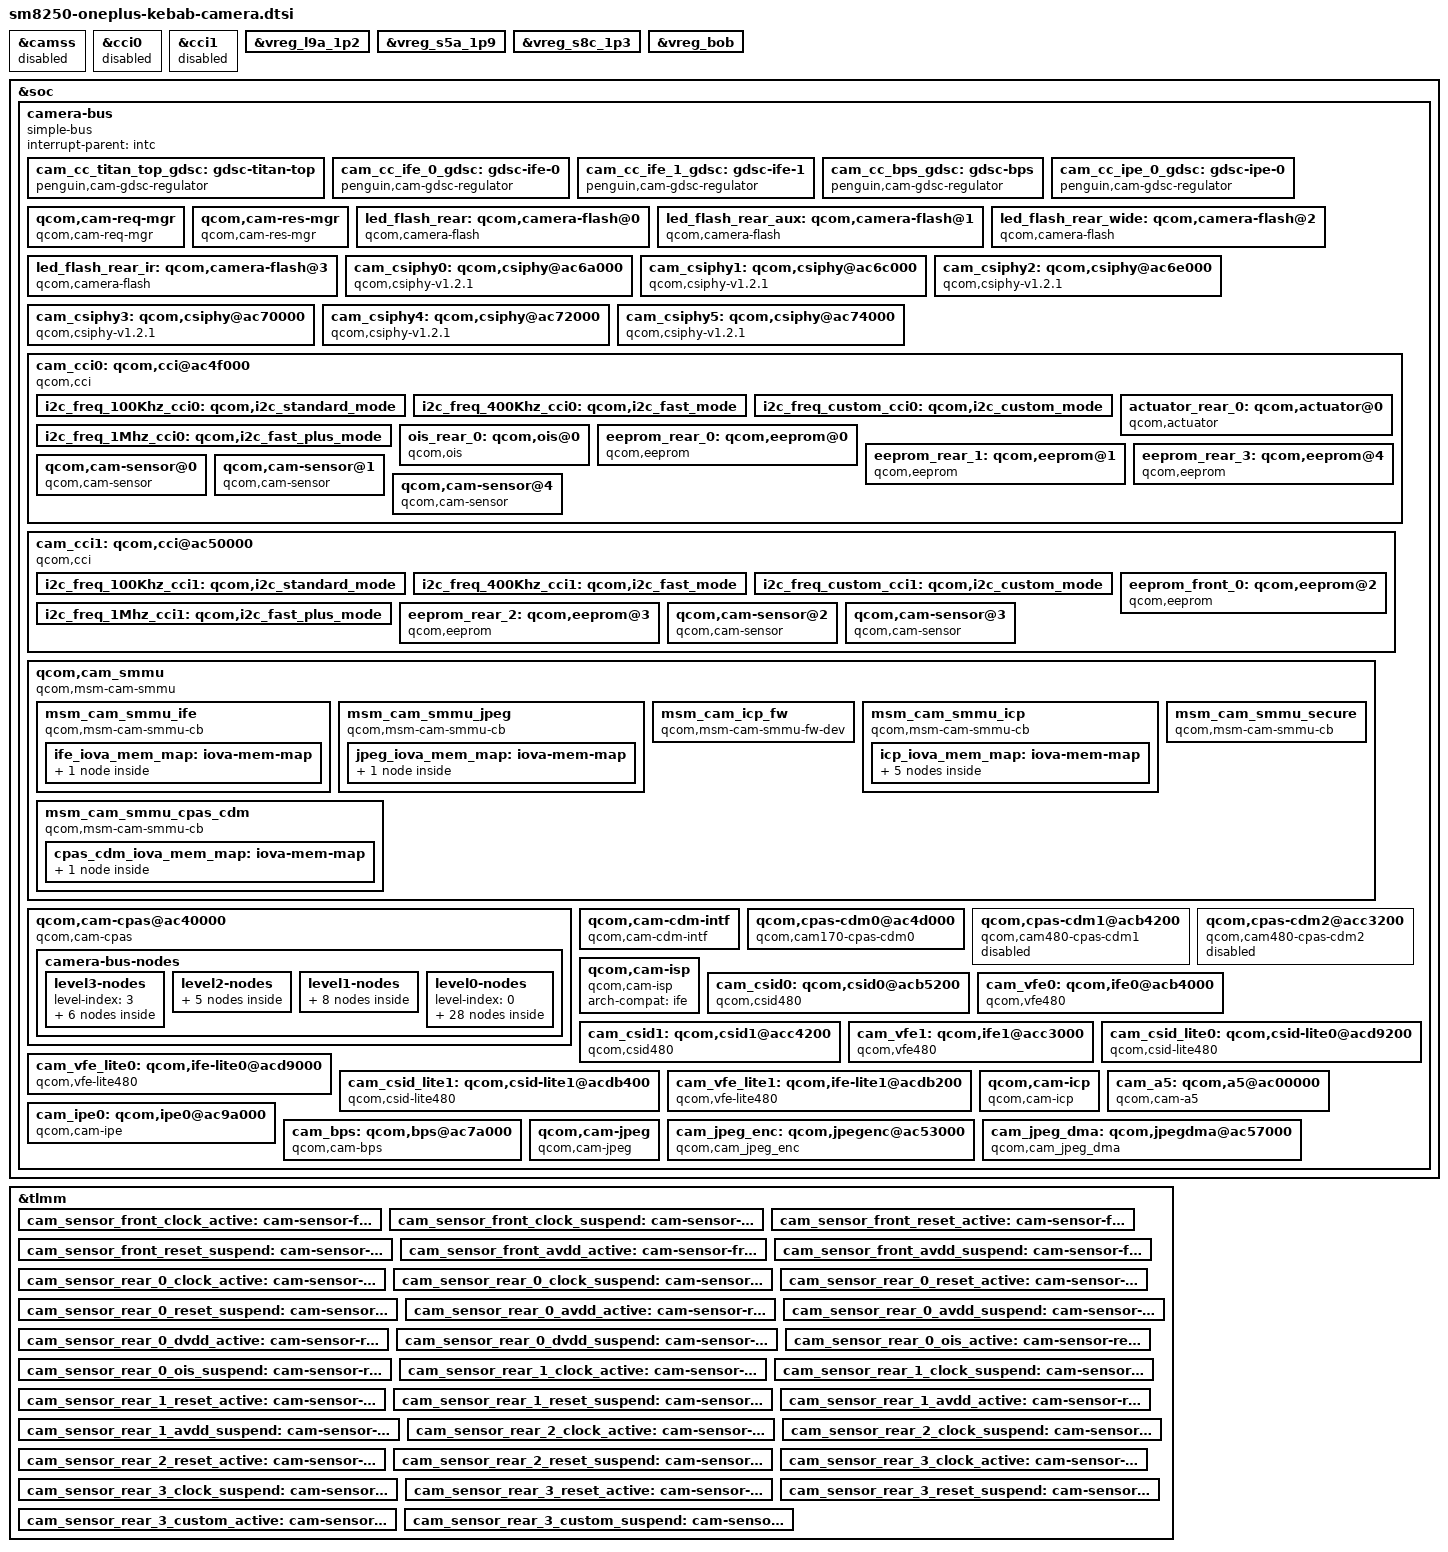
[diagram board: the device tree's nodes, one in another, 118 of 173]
// SPDX-License-Identifier: BSD-3-Clause
/*
 * Qualcomm Titan 480 camera subsystem and OnePlus 8T (kebab) sensor topology
 * for out-of-tree kona-camera-kernel on mainline Linux 6.18.
 */

#include <dt-bindings/clock/qcom,camcc-sm8250.h>
#include <dt-bindings/clock/qcom,gcc-sm8250.h>
#include <dt-bindings/interconnect/qcom,icc.h>
#include <dt-bindings/interconnect/qcom,sm8250.h>
#include <dt-bindings/msm-camera.h>
#include <dt-bindings/power/qcom,rpmhpd.h>
#include <dt-bindings/regulator/qcom,rpmh-regulator.h>

/* Keep mainline CAMSS and CCI disabled so kona-camera-kernel owns Titan 480. */
&camss {
	status = "disabled";
};

&cci0 {
	status = "disabled";
};

&cci1 {
	status = "disabled";
};

/* Allow camera drivers to vote regulator loads on shared RPMh rails. */
&vreg_l9a_1p2 {
	regulator-allow-set-load;
	regulator-allowed-modes = <RPMH_REGULATOR_MODE_HPM>;
};

&vreg_s5a_1p9 {
	regulator-allow-set-load;
	regulator-allowed-modes = <RPMH_REGULATOR_MODE_HPM>;
};

&vreg_s8c_1p3 {
	regulator-allow-set-load;
	regulator-allowed-modes = <RPMH_REGULATOR_MODE_HPM>;
};

&vreg_bob {
	regulator-allow-set-load;
	regulator-allowed-modes = <RPMH_REGULATOR_MODE_AUTO RPMH_REGULATOR_MODE_HPM>;
};

&soc {
	camera-bus {
		compatible = "simple-bus";
		#address-cells = <1>;
		#size-cells = <1>;
		ranges = <0x0 0x0 0x0 0xffffffff>;
		interrupt-parent = <&intc>;

		/* Mainline genpd -> regulator bridges for kona-camera-kernel */
		cam_cc_titan_top_gdsc: gdsc-titan-top {
			compatible = "penguin,cam-gdsc-regulator";
			regulator-name = "titan_top_gdsc";
			power-domains = <&camcc TITAN_TOP_GDSC>;
		};

		cam_cc_ife_0_gdsc: gdsc-ife-0 {
			compatible = "penguin,cam-gdsc-regulator";
			regulator-name = "ife_0_gdsc";
			power-domains = <&camcc IFE_0_GDSC>;
		};

		cam_cc_ife_1_gdsc: gdsc-ife-1 {
			compatible = "penguin,cam-gdsc-regulator";
			regulator-name = "ife_1_gdsc";
			power-domains = <&camcc IFE_1_GDSC>;
		};

		cam_cc_bps_gdsc: gdsc-bps {
			compatible = "penguin,cam-gdsc-regulator";
			regulator-name = "bps_gdsc";
			power-domains = <&camcc BPS_GDSC>;
		};

		cam_cc_ipe_0_gdsc: gdsc-ipe-0 {
			compatible = "penguin,cam-gdsc-regulator";
			regulator-name = "ipe_0_gdsc";
			power-domains = <&camcc IPE_0_GDSC>;
		};

		qcom,cam-req-mgr {
			compatible = "qcom,cam-req-mgr";
			status = "okay";
		};

		qcom,cam-res-mgr {
			compatible = "qcom,cam-res-mgr";
			status = "okay";
		};

		led_flash_rear: qcom,camera-flash@0 {
			cell-index = <0>;
			compatible = "qcom,camera-flash";
			flash-type = <CAM_FLASH_TYPE_PMIC>;
			leds = <&pm8150l_flash_led0>;
			status = "okay";
		};

		led_flash_rear_aux: qcom,camera-flash@1 {
			cell-index = <1>;
			compatible = "qcom,camera-flash";
			flash-type = <CAM_FLASH_TYPE_PMIC>;
			leds = <&pm8150l_flash_led0>;
			status = "okay";
		};

		led_flash_rear_wide: qcom,camera-flash@2 {
			cell-index = <2>;
			compatible = "qcom,camera-flash";
			flash-type = <CAM_FLASH_TYPE_PMIC>;
			leds = <&pm8150l_flash_led0>;
			status = "okay";
		};

		led_flash_rear_ir: qcom,camera-flash@3 {
			cell-index = <3>;
			compatible = "qcom,camera-flash";
			flash-type = <CAM_FLASH_TYPE_PMIC>;
			leds = <&pm8150l_flash_led0>;
			status = "okay";
		};

		cam_csiphy0: qcom,csiphy@ac6a000 {
			cell-index = <0>;
			compatible = "qcom,csiphy-v1.2.1", "qcom,csiphy";
			reg = <0x0ac6a000 0x2000>;
			reg-names = "csiphy";
			reg-cam-base = <0x6a000>;
			interrupts = <GIC_SPI 477 IRQ_TYPE_EDGE_RISING>;
			interrupt-names = "csiphy";
			gdscr-supply = <&cam_cc_titan_top_gdsc>;
			refgen-supply = <&refgen>;
			regulator-names = "gdscr", "refgen";
			csi-vdd-voltage = <1200000>;
			mipi-csi-vdd-supply = <&vreg_l9a_1p2>;
			clocks = <&camcc CAM_CC_CPHY_RX_CLK_SRC>,
				 <&camcc CAM_CC_CSIPHY0_CLK>,
				 <&camcc CAM_CC_CSI0PHYTIMER_CLK_SRC>,
				 <&camcc CAM_CC_CSI0PHYTIMER_CLK>;
			clock-names = "cphy_rx_clk_src",
				      "csiphy0_clk",
				      "csi0phytimer_clk_src",
				      "csi0phytimer_clk";
			src-clock-name = "csi0phytimer_clk_src";
			clock-cntl-level = "turbo";
			clock-rates = <400000000 0 300000000 0>;
			status = "okay";
		};

		cam_csiphy1: qcom,csiphy@ac6c000 {
			cell-index = <1>;
			compatible = "qcom,csiphy-v1.2.1", "qcom,csiphy";
			reg = <0x0ac6c000 0x2000>;
			reg-names = "csiphy";
			reg-cam-base = <0x6c000>;
			interrupts = <GIC_SPI 478 IRQ_TYPE_EDGE_RISING>;
			interrupt-names = "csiphy";
			gdscr-supply = <&cam_cc_titan_top_gdsc>;
			refgen-supply = <&refgen>;
			regulator-names = "gdscr", "refgen";
			csi-vdd-voltage = <1200000>;
			mipi-csi-vdd-supply = <&vreg_l9a_1p2>;
			clocks = <&camcc CAM_CC_CPHY_RX_CLK_SRC>,
				 <&camcc CAM_CC_CSIPHY1_CLK>,
				 <&camcc CAM_CC_CSI1PHYTIMER_CLK_SRC>,
				 <&camcc CAM_CC_CSI1PHYTIMER_CLK>;
			clock-names = "cphy_rx_clk_src",
				      "csiphy1_clk",
				      "csi1phytimer_clk_src",
				      "csi1phytimer_clk";
			src-clock-name = "csi1phytimer_clk_src";
			clock-cntl-level = "turbo";
			clock-rates = <400000000 0 300000000 0>;
			status = "okay";
		};

		cam_csiphy2: qcom,csiphy@ac6e000 {
			cell-index = <2>;
			compatible = "qcom,csiphy-v1.2.1", "qcom,csiphy";
			reg = <0x0ac6e000 0x2000>;
			reg-names = "csiphy";
			reg-cam-base = <0x6e000>;
			interrupts = <GIC_SPI 479 IRQ_TYPE_EDGE_RISING>;
			interrupt-names = "csiphy";
			gdscr-supply = <&cam_cc_titan_top_gdsc>;
			refgen-supply = <&refgen>;
			regulator-names = "gdscr", "refgen";
			csi-vdd-voltage = <1200000>;
			mipi-csi-vdd-supply = <&vreg_l9a_1p2>;
			clocks = <&camcc CAM_CC_CPHY_RX_CLK_SRC>,
				 <&camcc CAM_CC_CSIPHY2_CLK>,
				 <&camcc CAM_CC_CSI2PHYTIMER_CLK_SRC>,
				 <&camcc CAM_CC_CSI2PHYTIMER_CLK>;
			clock-names = "cphy_rx_clk_src",
				      "csiphy2_clk",
				      "csi2phytimer_clk_src",
				      "csi2phytimer_clk";
			src-clock-name = "csi2phytimer_clk_src";
			clock-cntl-level = "turbo";
			clock-rates = <400000000 0 300000000 0>;
			status = "okay";
		};

		cam_csiphy3: qcom,csiphy@ac70000 {
			cell-index = <3>;
			compatible = "qcom,csiphy-v1.2.1", "qcom,csiphy";
			reg = <0x0ac70000 0x2000>;
			reg-names = "csiphy";
			reg-cam-base = <0x70000>;
			interrupts = <GIC_SPI 448 IRQ_TYPE_EDGE_RISING>;
			interrupt-names = "csiphy";
			gdscr-supply = <&cam_cc_titan_top_gdsc>;
			refgen-supply = <&refgen>;
			regulator-names = "gdscr", "refgen";
			csi-vdd-voltage = <1200000>;
			mipi-csi-vdd-supply = <&vreg_l9a_1p2>;
			clocks = <&camcc CAM_CC_CPHY_RX_CLK_SRC>,
				 <&camcc CAM_CC_CSIPHY3_CLK>,
				 <&camcc CAM_CC_CSI3PHYTIMER_CLK_SRC>,
				 <&camcc CAM_CC_CSI3PHYTIMER_CLK>;
			clock-names = "cphy_rx_clk_src",
				      "csiphy3_clk",
				      "csi3phytimer_clk_src",
				      "csi3phytimer_clk";
			src-clock-name = "csi3phytimer_clk_src";
			clock-cntl-level = "turbo";
			clock-rates = <400000000 0 300000000 0>;
			status = "okay";
		};

		cam_csiphy4: qcom,csiphy@ac72000 {
			cell-index = <4>;
			compatible = "qcom,csiphy-v1.2.1", "qcom,csiphy";
			reg = <0x0ac72000 0x2000>;
			reg-names = "csiphy";
			reg-cam-base = <0x72000>;
			interrupts = <GIC_SPI 86 IRQ_TYPE_EDGE_RISING>;
			interrupt-names = "csiphy";
			gdscr-supply = <&cam_cc_titan_top_gdsc>;
			refgen-supply = <&refgen>;
			regulator-names = "gdscr", "refgen";
			csi-vdd-voltage = <1200000>;
			mipi-csi-vdd-supply = <&vreg_l9a_1p2>;
			clocks = <&camcc CAM_CC_CPHY_RX_CLK_SRC>,
				 <&camcc CAM_CC_CSIPHY4_CLK>,
				 <&camcc CAM_CC_CSI4PHYTIMER_CLK_SRC>,
				 <&camcc CAM_CC_CSI4PHYTIMER_CLK>;
			clock-names = "cphy_rx_clk_src",
				      "csiphy4_clk",
				      "csi4phytimer_clk_src",
				      "csi4phytimer_clk";
			src-clock-name = "csi4phytimer_clk_src";
			clock-cntl-level = "turbo";
			clock-rates = <400000000 0 300000000 0>;
			status = "okay";
		};

		cam_csiphy5: qcom,csiphy@ac74000 {
			cell-index = <5>;
			compatible = "qcom,csiphy-v1.2.1", "qcom,csiphy";
			reg = <0x0ac74000 0x2000>;
			reg-names = "csiphy";
			reg-cam-base = <0x74000>;
			interrupts = <GIC_SPI 89 IRQ_TYPE_EDGE_RISING>;
			interrupt-names = "csiphy";
			gdscr-supply = <&cam_cc_titan_top_gdsc>;
			refgen-supply = <&refgen>;
			regulator-names = "gdscr", "refgen";
			csi-vdd-voltage = <1200000>;
			mipi-csi-vdd-supply = <&vreg_l9a_1p2>;
			clocks = <&camcc CAM_CC_CPHY_RX_CLK_SRC>,
				 <&camcc CAM_CC_CSIPHY5_CLK>,
				 <&camcc CAM_CC_CSI5PHYTIMER_CLK_SRC>,
				 <&camcc CAM_CC_CSI5PHYTIMER_CLK>;
			clock-names = "cphy_rx_clk_src",
				      "csiphy5_clk",
				      "csi5phytimer_clk_src",
				      "csi5phytimer_clk";
			src-clock-name = "csi5phytimer_clk_src";
			clock-cntl-level = "turbo";
			clock-rates = <400000000 0 300000000 0>;
			status = "okay";
		};

		cam_cci0: qcom,cci@ac4f000 {
			cell-index = <0>;
			compatible = "qcom,cci";
			#address-cells = <1>;
			#size-cells = <0>;
			reg = <0x0ac4f000 0x1000>;
			reg-names = "cci";
			reg-cam-base = <0x4f000>;
			interrupt-names = "cci";
			interrupts = <GIC_SPI 460 IRQ_TYPE_EDGE_RISING>;
			status = "okay";
			gdscr-supply = <&cam_cc_titan_top_gdsc>;
			regulator-names = "gdscr";
			clocks = <&camcc CAM_CC_CCI_0_CLK_SRC>,
				 <&camcc CAM_CC_CCI_0_CLK>;
			clock-names = "cci_0_clk_src",
				      "cci_0_clk";
			src-clock-name = "cci_0_clk_src";
			clock-cntl-level = "lowsvs";
			clock-rates = <37500000 0>;
			pinctrl-names = "cam_default", "cam_suspend";
			pinctrl-0 = <&cci0_default>;
			pinctrl-1 = <&cci0_sleep>;
			qcom,cam-gpio-list = <&tlmm 101 0>,
					     <&tlmm 102 0>,
					     <&tlmm 103 0>,
					     <&tlmm 104 0>;
			gpio-req-tbl-num = <0 1 2 3>;
			gpio-req-tbl-flags = <1 1 1 1>;
			gpio-req-tbl-label = "CCI_I2C_DATA0",
					     "CCI_I2C_CLK0",
					     "CCI_I2C_DATA1",
					     "CCI_I2C_CLK1";

			i2c_freq_100Khz_cci0: qcom,i2c_standard_mode {
				hw-thigh = <201>;
				hw-tlow = <174>;
				hw-tsu-sto = <204>;
				hw-tsu-sta = <231>;
				hw-thd-dat = <22>;
				hw-thd-sta = <162>;
				hw-tbuf = <227>;
				hw-scl-stretch-en = <0>;
				hw-trdhld = <6>;
				hw-tsp = <3>;
				cci-clk-src = <37500000>;
				status = "okay";
			};

			i2c_freq_400Khz_cci0: qcom,i2c_fast_mode {
				hw-thigh = <38>;
				hw-tlow = <56>;
				hw-tsu-sto = <40>;
				hw-tsu-sta = <40>;
				hw-thd-dat = <22>;
				hw-thd-sta = <35>;
				hw-tbuf = <62>;
				hw-scl-stretch-en = <0>;
				hw-trdhld = <6>;
				hw-tsp = <3>;
				cci-clk-src = <37500000>;
				status = "okay";
			};

			i2c_freq_custom_cci0: qcom,i2c_custom_mode {
				hw-thigh = <38>;
				hw-tlow = <56>;
				hw-tsu-sto = <40>;
				hw-tsu-sta = <40>;
				hw-thd-dat = <22>;
				hw-thd-sta = <35>;
				hw-tbuf = <62>;
				hw-scl-stretch-en = <1>;
				hw-trdhld = <6>;
				hw-tsp = <3>;
				cci-clk-src = <37500000>;
				status = "okay";
			};

			i2c_freq_1Mhz_cci0: qcom,i2c_fast_plus_mode {
				hw-thigh = <16>;
				hw-tlow = <22>;
				hw-tsu-sto = <17>;
				hw-tsu-sta = <18>;
				hw-thd-dat = <16>;
				hw-thd-sta = <15>;
				hw-tbuf = <24>;
				hw-scl-stretch-en = <0>;
				hw-trdhld = <3>;
				hw-tsp = <3>;
				cci-clk-src = <37500000>;
				status = "okay";
			};

			actuator_rear_0: qcom,actuator@0 {
				cell-index = <0>;
				reg = <0x0>;
				compatible = "qcom,actuator";
				cci-master = <0>;
				cam_vaf-supply = <&pm8008_l3>;
				regulator-names = "cam_vaf";
				rgltr-cntrl-support;
				rgltr-min-voltage = <2800000>;
				rgltr-max-voltage = <2800000>;
				rgltr-load-current = <600000>;
			};

			ois_rear_0: qcom,ois@0 {
				cell-index = <0>;
				reg = <0x0>;
				compatible = "qcom,ois";
				cam_vio-supply = <&pm8008_l4>;
				cam_vdig-supply = <&vreg_s8c_1p3>;
				cam_vaf-supply = <&vreg_bob>;
				regulator-names = "cam_vio", "cam_vdig", "cam_vaf";
				rgltr-cntrl-support;
				rgltr-min-voltage = <0 1352000 3008000>;
				rgltr-max-voltage = <0 1352000 3800000>;
				rgltr-load-current = <1000000 1000000 1000000>;
				gpio-no-mux = <0>;
				pinctrl-names = "cam_default", "cam_suspend";
				pinctrl-0 = <&cam_sensor_rear_0_ois_active>;
				pinctrl-1 = <&cam_sensor_rear_0_ois_suspend>;
				qcom,cam-gpio-list = <&tlmm 140 0>;
				gpio-vaf = <0>;
				gpio-req-tbl-num = <0>;
				gpio-req-tbl-flags = <0>;
				gpio-req-tbl-label = "CAMIF_vaf";
				cci-master = <0>;
				status = "okay";
				ois_gyro,position = <3>;
				ois,type = <0>;
				ois_gyro,type = <3>;
				ois,name = "LC898124";
				ois_module,vendor = <0>;
				ois_actuator,vednor = <0>;
				ois,fw = <1>;
				download,fw = <1>;
			};

			/* EEPROM wide camera: IMX586 */
			eeprom_rear_0: qcom,eeprom@0 {
				cell-index = <0>;
				compatible = "qcom,eeprom";
				reg = <0x0>;
				cam_vio-supply = <&pm8008_l4>;
				cam_vdig-supply = <&vreg_s8c_1p3>;
				cam_vana-supply = <&pm8008_l7>;
				cam_v_custom1-supply = <&vreg_s5a_1p9>;
				cam_clk-supply = <&cam_cc_titan_top_gdsc>;
				regulator-names = "cam_vio", "cam_vdig", "cam_vana",
						  "cam_v_custom1", "cam_clk";
				rgltr-cntrl-support;
				rgltr-min-voltage = <0 1352000 2896000 2000000 0>;
				rgltr-max-voltage = <0 1352000 2904000 2000000 0>;
				rgltr-load-current = <1000000 1000000 300000 300000 0>;
				gpio-no-mux = <0>;
				pinctrl-names = "cam_default", "cam_suspend";
				pinctrl-0 = <&cam_sensor_rear_0_clock_active
					     &cam_sensor_rear_0_reset_active
					     &cam_sensor_rear_0_avdd_active
					     &cam_sensor_rear_0_dvdd_active>;
				pinctrl-1 = <&cam_sensor_rear_0_clock_suspend
					     &cam_sensor_rear_0_reset_suspend
					     &cam_sensor_rear_0_avdd_suspend
					     &cam_sensor_rear_0_dvdd_suspend>;
				qcom,cam-gpio-list = <&tlmm 94 0>,
						     <&tlmm 78 0>,
						     <&tlmm 139 0>,
						     <&tlmm 117 0>;
				use-shared-clk;
				gpio-reset = <1>;
				gpio-custom1 = <2>;
				gpio-vdig = <3>;
				gpio-req-tbl-num = <0 1 2 3>;
				gpio-req-tbl-flags = <1 0 0 0>;
				gpio-req-tbl-label = "CAM_MCLK0",
						     "CAM_RESET0",
						     "CAM_CUSTOM1",
						     "CAM_VDIG";
				sensor-mode = <0>;
				cci-master = <0>;
				status = "okay";
				clocks = <&camcc CAM_CC_MCLK0_CLK>;
				clock-names = "cam_clk";
				clock-cntl-level = "turbo";
				clock-rates = <19200000>;
			};

			/* EEPROM ultrawide camera: IMX481 */
			eeprom_rear_1: qcom,eeprom@1 {
				cell-index = <1>;
				compatible = "qcom,eeprom";
				reg = <0x1>;
				cam_vio-supply = <&pm8008_l4>;
				cam_vana-supply = <&vreg_bob>;
				cam_vdig-supply = <&pm8008_l1>;
				cam_clk-supply = <&cam_cc_titan_top_gdsc>;
				regulator-names = "cam_vio", "cam_vdig", "cam_vana", "cam_clk";
				rgltr-cntrl-support;
				rgltr-min-voltage = <0 1096000 3008000 0>;
				rgltr-max-voltage = <0 1104000 3800000 0>;
				rgltr-load-current = <1000000 1000000 300000 0>;
				gpio-no-mux = <0>;
				pinctrl-names = "cam_default", "cam_suspend";
				pinctrl-0 = <&cam_sensor_rear_1_clock_active
					     &cam_sensor_rear_1_reset_active
					     &cam_sensor_rear_1_avdd_active>;
				pinctrl-1 = <&cam_sensor_rear_1_clock_suspend
					     &cam_sensor_rear_1_reset_suspend
					     &cam_sensor_rear_1_avdd_suspend>;
				qcom,cam-gpio-list = <&tlmm 95 0>,
						     <&tlmm 84 0>,
						     <&tlmm 114 0>;
				use-shared-clk;
				gpio-reset = <1>;
				gpio-vana = <2>;
				gpio-req-tbl-num = <0 1 2>;
				gpio-req-tbl-flags = <1 0 0>;
				gpio-req-tbl-label = "CAM_MCLK1",
						     "CAM_RESET1",
						     "CAM_VANA1";
				sensor-mode = <0>;
				cci-master = <1>;
				status = "okay";
				clocks = <&camcc CAM_CC_MCLK1_CLK>;
				clock-names = "cam_clk";
				clock-cntl-level = "turbo";
				clock-rates = <19200000>;
			};

			/* EEPROM monochrome camera: GC02M1B */
			eeprom_rear_3: qcom,eeprom@4 {
				cell-index = <4>;
				compatible = "qcom,eeprom";
				reg = <0x4>;
				cam_vio-supply = <&pm8008_l4>;
				cam_vdig-supply = <&pm8008_l4>;
				cam_vana-supply = <&pm8008_l5>;
				cam_clk-supply = <&cam_cc_titan_top_gdsc>;
				regulator-names = "cam_vio", "cam_vdig", "cam_vana", "cam_clk";
				rgltr-cntrl-support;
				rgltr-min-voltage = <0 1800000 2800000 0>;
				rgltr-max-voltage = <0 1800000 2800000 0>;
				rgltr-load-current = <0 300000 300000 0>;
				gpio-no-mux = <0>;
				pinctrl-names = "cam_default", "cam_suspend";
				pinctrl-0 = <&cam_sensor_rear_3_clock_active
					     &cam_sensor_rear_3_reset_active
					     &cam_sensor_rear_3_custom_active>;
				pinctrl-1 = <&cam_sensor_rear_3_clock_suspend
					     &cam_sensor_rear_3_reset_suspend
					     &cam_sensor_rear_3_custom_suspend>;
				qcom,cam-gpio-list = <&tlmm 96 0>,
						     <&tlmm 90 0>,
						     <&tlmm 74 0>;
				use-shared-clk;
				gpio-reset = <1>;
				gpio-custom1 = <2>;
				gpio-req-tbl-num = <0 1 2>;
				gpio-req-tbl-flags = <1 0 0>;
				gpio-req-tbl-label = "CAM_MCLK4",
						     "CAM_RESET4",
						     "CAM_RESET_NEW";
				sensor-mode = <0>;
				cci-master = <1>;
				status = "okay";
				clocks = <&camcc CAM_CC_MCLK2_CLK>;
				clock-names = "cam_clk";
				clock-cntl-level = "turbo";
				clock-rates = <19200000>;
			};

			/* Wide camera: IMX586 */
			qcom,cam-sensor@0 {
				cell-index = <0>;
				compatible = "qcom,cam-sensor";
				reg = <0x0>;
				csiphy-sd-index = <0>;
				sensor-position-roll = <90>;
				sensor-position-pitch = <0>;
				sensor-position-yaw = <180>;
				actuator-src = <&actuator_rear_0>;
				eeprom-src = <&eeprom_rear_0>;
				ois-src = <&ois_rear_0>;
				led-flash-src = <&led_flash_rear>;
				cam_vio-supply = <&pm8008_l4>;
				cam_vdig-supply = <&vreg_s8c_1p3>;
				cam_vana-supply = <&pm8008_l7>;
				cam_v_custom1-supply = <&vreg_s5a_1p9>;
				cam_vaf-supply = <&pm8008_l3>;
				cam_clk-supply = <&cam_cc_titan_top_gdsc>;
				regulator-names = "cam_vio", "cam_vdig", "cam_vana",
						  "cam_v_custom1", "cam_vaf", "cam_clk";
				rgltr-cntrl-support;
				rgltr-min-voltage = <0 1352000 2896000 2000000 2800000 0>;
				rgltr-max-voltage = <0 1352000 2904000 2000000 2800000 0>;
				rgltr-load-current = <1000000 1000000 300000 300000 1000000 0>;
				gpio-no-mux = <0>;
				pinctrl-names = "cam_default", "cam_suspend";
				pinctrl-0 = <&cam_sensor_rear_0_clock_active
					     &cam_sensor_rear_0_reset_active
					     &cam_sensor_rear_0_avdd_active
					     &cam_sensor_rear_0_dvdd_active>;
				pinctrl-1 = <&cam_sensor_rear_0_clock_suspend
					     &cam_sensor_rear_0_reset_suspend
					     &cam_sensor_rear_0_avdd_suspend
					     &cam_sensor_rear_0_dvdd_suspend>;
				qcom,cam-gpio-list = <&tlmm 94 0>,
						     <&tlmm 78 0>,
						     <&tlmm 139 0>,
						     <&tlmm 117 0>;
				use-shared-clk;
				gpio-reset = <1>;
				gpio-custom1 = <2>;
				gpio-vdig = <3>;
				gpio-req-tbl-num = <0 1 2 3>;
				gpio-req-tbl-flags = <1 0 0 0>;
				gpio-req-tbl-label = "CAM_MCLK0",
						     "CAM_RESET0",
						     "CAM_CUSTOM1",
						     "CAM_VDIG";
				sensor-mode = <0>;
				cci-master = <0>;
				status = "okay";
				clocks = <&camcc CAM_CC_MCLK0_CLK>;
				clock-names = "cam_clk";
				clock-cntl-level = "turbo";
				clock-rates = <19200000>;
			};

			/* Ultrawide camera: IMX481 */
			qcom,cam-sensor@1 {
				cell-index = <1>;
				compatible = "qcom,cam-sensor";
				reg = <0x1>;
				csiphy-sd-index = <1>;
				sensor-position-roll = <90>;
				sensor-position-pitch = <0>;
				sensor-position-yaw = <180>;
				eeprom-src = <&eeprom_rear_1>;
				led-flash-src = <&led_flash_rear_wide>;
				cam_vio-supply = <&pm8008_l4>;
				cam_vana-supply = <&vreg_bob>;
				cam_vdig-supply = <&pm8008_l1>;
				cam_clk-supply = <&cam_cc_titan_top_gdsc>;
				regulator-names = "cam_vio", "cam_vdig", "cam_vana", "cam_clk";
				rgltr-cntrl-support;
				rgltr-min-voltage = <0 1096000 3300000 0>;
				rgltr-max-voltage = <0 1104000 3800000 0>;
				rgltr-load-current = <1000000 1000000 300000 0>;
				gpio-no-mux = <0>;
				pinctrl-names = "cam_default", "cam_suspend";
				pinctrl-0 = <&cam_sensor_rear_1_clock_active
					     &cam_sensor_rear_1_reset_active
					     &cam_sensor_rear_1_avdd_active>;
				pinctrl-1 = <&cam_sensor_rear_1_clock_suspend
					     &cam_sensor_rear_1_reset_suspend
					     &cam_sensor_rear_1_avdd_suspend>;
				qcom,cam-gpio-list = <&tlmm 95 0>,
						     <&tlmm 84 0>,
						     <&tlmm 114 0>;
				use-shared-clk;
				gpio-reset = <1>;
				gpio-vana = <2>;
				gpio-req-tbl-num = <0 1 2>;
				gpio-req-tbl-flags = <1 0 0>;
				gpio-req-tbl-label = "CAM_MCLK1",
						     "CAM_RESET1",
						     "CAM_VANA1";
				sensor-mode = <0>;
				cci-master = <1>;
				status = "okay";
				clocks = <&camcc CAM_CC_MCLK1_CLK>;
				clock-names = "cam_clk";
				clock-cntl-level = "turbo";
				clock-rates = <19200000>;
			};

			/* Monochrome camera: GC02M1B */
			qcom,cam-sensor@4 {
				cell-index = <4>;
				compatible = "qcom,cam-sensor";
				reg = <0x4>;
				csiphy-sd-index = <2>;
				sensor-position-roll = <90>;
				sensor-position-pitch = <0>;
				sensor-position-yaw = <180>;
				eeprom-src = <&eeprom_rear_3>;
				led-flash-src = <&led_flash_rear_aux>;
				cam_vio-supply = <&pm8008_l4>;
				cam_vdig-supply = <&pm8008_l4>;
				cam_vana-supply = <&pm8008_l5>;
				cam_clk-supply = <&cam_cc_titan_top_gdsc>;
				regulator-names = "cam_vio", "cam_vdig", "cam_vana", "cam_clk";
				rgltr-cntrl-support;
				rgltr-min-voltage = <0 1800000 2800000 0>;
				rgltr-max-voltage = <0 1800000 2800000 0>;
				rgltr-load-current = <0 300000 300000 0>;
				gpio-no-mux = <0>;
				pinctrl-names = "cam_default", "cam_suspend";
				pinctrl-0 = <&cam_sensor_rear_3_clock_active
					     &cam_sensor_rear_3_reset_active
					     &cam_sensor_rear_3_custom_active>;
				pinctrl-1 = <&cam_sensor_rear_3_clock_suspend
					     &cam_sensor_rear_3_reset_suspend
					     &cam_sensor_rear_3_custom_suspend>;
				qcom,cam-gpio-list = <&tlmm 96 0>,
						     <&tlmm 90 0>,
						     <&tlmm 74 0>;
				use-shared-clk;
				gpio-reset = <1>;
				gpio-custom1 = <2>;
				gpio-req-tbl-num = <0 1 2>;
				gpio-req-tbl-flags = <1 0 0>;
				gpio-req-tbl-label = "CAM_MCLK4",
						     "CAM_RESET4",
						     "CAM_RESET_NEW";
				sensor-mode = <0>;
				cci-master = <1>;
				status = "okay";
				clocks = <&camcc CAM_CC_MCLK2_CLK>;
				clock-names = "cam_clk";
				clock-cntl-level = "turbo";
				clock-rates = <19200000>;
			};
		};

		cam_cci1: qcom,cci@ac50000 {
			cell-index = <1>;
			compatible = "qcom,cci";
			#address-cells = <1>;
			#size-cells = <0>;
			reg = <0x0ac50000 0x1000>;
			reg-names = "cci";
			reg-cam-base = <0x50000>;
			interrupt-names = "cci";
			interrupts = <GIC_SPI 271 IRQ_TYPE_EDGE_RISING>;
			status = "okay";
			gdscr-supply = <&cam_cc_titan_top_gdsc>;
			regulator-names = "gdscr";
			clocks = <&camcc CAM_CC_CCI_1_CLK_SRC>,
				 <&camcc CAM_CC_CCI_1_CLK>;
			clock-names = "cci_1_clk_src",
				      "cci_1_clk";
			src-clock-name = "cci_1_clk_src";
			clock-cntl-level = "lowsvs";
			clock-rates = <37500000 0>;
			pinctrl-names = "cam_default", "cam_suspend";
			pinctrl-0 = <&cci1_default>;
			pinctrl-1 = <&cci1_sleep>;
			qcom,cam-gpio-list = <&tlmm 105 0>,
					     <&tlmm 106 0>,
					     <&tlmm 107 0>,
					     <&tlmm 108 0>;
			gpio-req-tbl-num = <0 1 2 3>;
			gpio-req-tbl-flags = <1 1 1 1>;
			gpio-req-tbl-label = "CCI_I2C_DATA2",
					     "CCI_I2C_CLK2",
					     "CCI_I2C_DATA3",
					     "CCI_I2C_CLK3";

			i2c_freq_100Khz_cci1: qcom,i2c_standard_mode {
				hw-thigh = <201>;
				hw-tlow = <174>;
				hw-tsu-sto = <204>;
				hw-tsu-sta = <231>;
				hw-thd-dat = <22>;
				hw-thd-sta = <162>;
				hw-tbuf = <227>;
				hw-scl-stretch-en = <0>;
				hw-trdhld = <6>;
				hw-tsp = <3>;
				cci-clk-src = <37500000>;
				status = "okay";
			};

			i2c_freq_400Khz_cci1: qcom,i2c_fast_mode {
				hw-thigh = <38>;
				hw-tlow = <56>;
				hw-tsu-sto = <40>;
				hw-tsu-sta = <40>;
				hw-thd-dat = <22>;
				hw-thd-sta = <35>;
				hw-tbuf = <62>;
				hw-scl-stretch-en = <0>;
				hw-trdhld = <6>;
				hw-tsp = <3>;
				cci-clk-src = <37500000>;
				status = "okay";
			};

			i2c_freq_custom_cci1: qcom,i2c_custom_mode {
				hw-thigh = <38>;
				hw-tlow = <56>;
				hw-tsu-sto = <40>;
				hw-tsu-sta = <40>;
				hw-thd-dat = <22>;
				hw-thd-sta = <35>;
				hw-tbuf = <62>;
				hw-scl-stretch-en = <1>;
				hw-trdhld = <6>;
				hw-tsp = <3>;
				cci-clk-src = <37500000>;
				status = "okay";
			};

			i2c_freq_1Mhz_cci1: qcom,i2c_fast_plus_mode {
				hw-thigh = <16>;
				hw-tlow = <22>;
				hw-tsu-sto = <17>;
				hw-tsu-sta = <18>;
				hw-thd-dat = <16>;
				hw-thd-sta = <15>;
				hw-tbuf = <24>;
				hw-scl-stretch-en = <0>;
				hw-trdhld = <3>;
				hw-tsp = <3>;
				cci-clk-src = <37500000>;
				status = "okay";
			};

			/* EEPROM front camera: IMX471 */
			eeprom_front_0: qcom,eeprom@2 {
				cell-index = <2>;
				compatible = "qcom,eeprom";
				reg = <0x2>;
				cam_vio-supply = <&pm8008_l4>;
				cam_vdig-supply = <&pm8008_l1>;
				cam_vana-supply = <&vreg_bob>;
				cam_clk-supply = <&cam_cc_titan_top_gdsc>;
				regulator-names = "cam_vio", "cam_vdig", "cam_vana", "cam_clk";
				rgltr-cntrl-support;
				rgltr-min-voltage = <0 1096000 3008000 0>;
				rgltr-max-voltage = <0 1104000 3800000 0>;
				rgltr-load-current = <1000000 1000000 300000 0>;
				gpio-no-mux = <0>;
				pinctrl-names = "cam_default", "cam_suspend";
				pinctrl-0 = <&cam_sensor_front_clock_active
					     &cam_sensor_front_reset_active
					     &cam_sensor_front_avdd_active>;
				pinctrl-1 = <&cam_sensor_front_clock_suspend
					     &cam_sensor_front_reset_suspend
					     &cam_sensor_front_avdd_suspend>;
				qcom,cam-gpio-list = <&tlmm 98 0>,
						     <&tlmm 144 0>,
						     <&tlmm 156 0>;
				use-shared-clk;
				gpio-reset = <1>;
				gpio-vana = <2>;
				gpio-req-tbl-num = <0 1 2>;
				gpio-req-tbl-flags = <1 0 0>;
				gpio-req-tbl-label = "CAM_front_MCLK",
						     "CAM_front_RESET",
						     "CAM_front_VANA";
				sensor-mode = <0>;
				cci-master = <1>;
				status = "okay";
				clocks = <&camcc CAM_CC_MCLK4_CLK>;
				clock-names = "cam_clk";
				clock-cntl-level = "turbo";
				clock-rates = <19200000>;
			};

			/* EEPROM macro camera: GC5035 */
			eeprom_rear_2: qcom,eeprom@3 {
				cell-index = <3>;
				compatible = "qcom,eeprom";
				reg = <0x3>;
				cam_vio-supply = <&pm8008_l4>;
				cam_vdig-supply = <&pm8008_l2>;
				cam_vana-supply = <&pm8008_l6>;
				cam_clk-supply = <&cam_cc_titan_top_gdsc>;
				regulator-names = "cam_vio", "cam_vdig", "cam_vana", "cam_clk";
				rgltr-cntrl-support;
				rgltr-min-voltage = <0 1200000 2800000 0>;
				rgltr-max-voltage = <0 1200000 2800000 0>;
				rgltr-load-current = <1000000 1000000 300000 0>;
				gpio-no-mux = <0>;
				pinctrl-names = "cam_default", "cam_suspend";
				pinctrl-0 = <&cam_sensor_rear_2_clock_active
					     &cam_sensor_rear_2_reset_active>;
				pinctrl-1 = <&cam_sensor_rear_2_clock_suspend
					     &cam_sensor_rear_2_reset_suspend>;
				qcom,cam-gpio-list = <&tlmm 97 0>,
						     <&tlmm 92 0>;
				use-shared-clk;
				gpio-reset = <1>;
				gpio-req-tbl-num = <0 1>;
				gpio-req-tbl-flags = <1 0>;
				gpio-req-tbl-label = "CAM_MCLK2",
						     "CAM_RESET2";
				sensor-mode = <0>;
				cci-master = <0>;
				status = "okay";
				clocks = <&camcc CAM_CC_MCLK3_CLK>;
				clock-names = "cam_clk";
				clock-cntl-level = "turbo";
				clock-rates = <19200000>;
			};

			/* Front camera: IMX471 */
			qcom,cam-sensor@2 {
				cell-index = <2>;
				compatible = "qcom,cam-sensor";
				reg = <0x2>;
				csiphy-sd-index = <4>;
				sensor-position-roll = <270>;
				sensor-position-pitch = <0>;
				sensor-position-yaw = <0>;
				eeprom-src = <&eeprom_front_0>;
				cam_vio-supply = <&pm8008_l4>;
				cam_vdig-supply = <&pm8008_l1>;
				cam_vana-supply = <&vreg_bob>;
				cam_clk-supply = <&cam_cc_titan_top_gdsc>;
				regulator-names = "cam_vio", "cam_vdig", "cam_vana", "cam_clk";
				rgltr-cntrl-support;
				rgltr-min-voltage = <0 1096000 3008000 0>;
				rgltr-max-voltage = <0 1104000 3800000 0>;
				rgltr-load-current = <1000000 1000000 300000 0>;
				gpio-no-mux = <0>;
				pinctrl-names = "cam_default", "cam_suspend";
				pinctrl-0 = <&cam_sensor_front_clock_active
					     &cam_sensor_front_reset_active
					     &cam_sensor_front_avdd_active>;
				pinctrl-1 = <&cam_sensor_front_clock_suspend
					     &cam_sensor_front_reset_suspend
					     &cam_sensor_front_avdd_suspend>;
				qcom,cam-gpio-list = <&tlmm 98 0>,
						     <&tlmm 144 0>,
						     <&tlmm 156 0>;
				use-shared-clk;
				gpio-reset = <1>;
				gpio-vana = <2>;
				gpio-req-tbl-num = <0 1 2>;
				gpio-req-tbl-flags = <1 0 0>;
				gpio-req-tbl-label = "CAM_front_MCLK",
						     "CAM_front_RESET",
						     "CAM_front_VANA";
				sensor-mode = <0>;
				cci-master = <1>;
				status = "okay";
				clocks = <&camcc CAM_CC_MCLK4_CLK>;
				clock-names = "cam_clk";
				clock-cntl-level = "turbo";
				clock-rates = <19200000>;
			};

			/* Macro camera: GC5035 */
			qcom,cam-sensor@3 {
				cell-index = <3>;
				compatible = "qcom,cam-sensor";
				reg = <0x3>;
				csiphy-sd-index = <3>;
				sensor-position-roll = <90>;
				sensor-position-pitch = <0>;
				sensor-position-yaw = <180>;
				eeprom-src = <&eeprom_rear_2>;
				led-flash-src = <&led_flash_rear_ir>;
				cam_vio-supply = <&pm8008_l4>;
				cam_vdig-supply = <&pm8008_l2>;
				cam_vana-supply = <&pm8008_l6>;
				cam_clk-supply = <&cam_cc_titan_top_gdsc>;
				regulator-names = "cam_vio", "cam_vdig", "cam_vana", "cam_clk";
				rgltr-cntrl-support;
				rgltr-min-voltage = <0 1200000 2800000 0>;
				rgltr-max-voltage = <0 1200000 2800000 0>;
				rgltr-load-current = <1000000 1000000 300000 0>;
				gpio-no-mux = <0>;
				pinctrl-names = "cam_default", "cam_suspend";
				pinctrl-0 = <&cam_sensor_rear_2_clock_active
					     &cam_sensor_rear_2_reset_active>;
				pinctrl-1 = <&cam_sensor_rear_2_clock_suspend
					     &cam_sensor_rear_2_reset_suspend>;
				qcom,cam-gpio-list = <&tlmm 97 0>,
						     <&tlmm 92 0>;
				use-shared-clk;
				gpio-reset = <1>;
				gpio-req-tbl-num = <0 1>;
				gpio-req-tbl-flags = <1 0>;
				gpio-req-tbl-label = "CAM_MCLK2",
						     "CAM_RESET2";
				sensor-mode = <0>;
				cci-master = <0>;
				status = "okay";
				clocks = <&camcc CAM_CC_MCLK3_CLK>;
				clock-names = "cam_clk";
				clock-cntl-level = "turbo";
				clock-rates = <19200000>;
			};
		};

		qcom,cam_smmu {
			compatible = "qcom,msm-cam-smmu";
			status = "okay";

			msm_cam_smmu_ife {
				compatible = "qcom,msm-cam-smmu-cb";
				iommus = <&apps_smmu 0x800 0x400>,
					 <&apps_smmu 0x801 0x400>,
					 <&apps_smmu 0x840 0x400>,
					 <&apps_smmu 0x841 0x400>,
					 <&apps_smmu 0xc00 0x400>,
					 <&apps_smmu 0xc01 0x400>,
					 <&apps_smmu 0xc40 0x400>,
					 <&apps_smmu 0xc41 0x400>;
				qcom,iommu-dma-addr-pool = <0x7400000 0xd8c00000>;
				label = "ife";
				ife_iova_mem_map: iova-mem-map {
					iova-mem-region-io {
						iova-region-name = "io";
						iova-region-start = <0x7400000>;
						iova-region-len = <0xd8c00000>;
						iova-region-id = <0x3>;
						status = "okay";
					};
				};
			};

			msm_cam_smmu_jpeg {
				compatible = "qcom,msm-cam-smmu-cb";
				iommus = <&apps_smmu 0x2040 0x400>,
					 <&apps_smmu 0x2440 0x400>;
				label = "jpeg";
				qcom,iommu-dma-addr-pool = <0x7400000 0xd8c00000>;
				jpeg_iova_mem_map: iova-mem-map {
					iova-mem-region-io {
						iova-region-name = "io";
						iova-region-start = <0x7400000>;
						iova-region-len = <0xd8c00000>;
						iova-region-id = <0x3>;
						status = "okay";
					};
				};
			};

			msm_cam_icp_fw {
				compatible = "qcom,msm-cam-smmu-fw-dev";
				label = "icp";
				memory-region = <&camera_mem>;
			};

			msm_cam_smmu_icp {
				compatible = "qcom,msm-cam-smmu-cb";
				iommus = <&apps_smmu 0x20e2 0x400>,
					 <&apps_smmu 0x24e2 0x400>,
					 <&apps_smmu 0x2000 0x400>,
					 <&apps_smmu 0x2001 0x400>,
					 <&apps_smmu 0x2400 0x400>,
					 <&apps_smmu 0x2401 0x400>,
					 <&apps_smmu 0x2060 0x400>,
					 <&apps_smmu 0x2061 0x400>,
					 <&apps_smmu 0x2460 0x400>,
					 <&apps_smmu 0x2461 0x400>,
					 <&apps_smmu 0x2020 0x400>,
					 <&apps_smmu 0x2021 0x400>,
					 <&apps_smmu 0x2420 0x400>,
					 <&apps_smmu 0x2421 0x400>;
				label = "icp";
				qcom,iommu-dma-addr-pool = <0x10c00000 0xee300000>;
				iova-region-discard = <0xdff00000 0x300000>;
				icp_iova_mem_map: iova-mem-map {
					iova-mem-region-firmware {
						iova-region-name = "firmware";
						iova-region-start = <0x0>;
						iova-region-len = <0x500000>;
						iova-region-id = <0x0>;
						status = "okay";
					};

					iova-mem-region-shared {
						iova-region-name = "shared";
						iova-region-start = <0x7400000>;
						iova-region-len = <0x9600000>;
						iova-region-id = <0x1>;
						status = "okay";
					};

					iova-mem-region-secondary-heap {
						iova-region-name = "secheap";
						iova-region-start = <0x10a00000>;
						iova-region-len = <0x100000>;
						iova-region-id = <0x4>;
						status = "okay";
					};

					iova-mem-region-io {
						iova-region-name = "io";
						iova-region-start = <0x10c00000>;
						iova-region-len = <0xee300000>;
						iova-region-id = <0x3>;
						iova-region-discard = <0xdff00000 0x300000>;
						status = "okay";
					};

					iova-mem-qdss-region {
						iova-region-name = "qdss";
						iova-region-start = <0x10b00000>;
						iova-region-len = <0x100000>;
						iova-region-id = <0x5>;
						qdss-phy-addr = <0x16790000>;
						status = "okay";
					};
				};
			};

			msm_cam_smmu_cpas_cdm {
				compatible = "qcom,msm-cam-smmu-cb";
				iommus = <&apps_smmu 0x20c0 0x400>,
					 <&apps_smmu 0x24c0 0x400>;
				label = "cpas-cdm0";
				qcom,iommu-dma-addr-pool = <0x7400000 0xd8c00000>;
				cpas_cdm_iova_mem_map: iova-mem-map {
					iova-mem-region-io {
						iova-region-name = "io";
						iova-region-start = <0x7400000>;
						iova-region-len = <0xd8c00000>;
						iova-region-id = <0x3>;
						status = "okay";
					};
				};
			};

			msm_cam_smmu_secure {
				compatible = "qcom,msm-cam-smmu-cb";
				label = "cam-secure";
				qcom,secure-cb;
			};
		};

		qcom,cam-cpas@ac40000 {
			cell-index = <0>;
			compatible = "qcom,cam-cpas";
			label = "cpas";
			arch-compat = "cpas_top";
			status = "okay";
			reg-names = "cam_cpas_top", "cam_camnoc";
			reg = <0x0ac40000 0x1000>,
			      <0x0ac42000 0x8000>;
			reg-cam-base = <0x40000 0x42000>;
			interrupt-names = "cpas_camnoc";
			interrupts = <GIC_SPI 459 IRQ_TYPE_EDGE_RISING>;
			camnoc-axi-min-ib-bw = <3000000000>;
			regulator-names = "camss-vdd";
			camss-vdd-supply = <&cam_cc_titan_top_gdsc>;
			clock-names = "gcc_axi_hf_clk",
				      "gcc_axi_sf_clk",
				      "slow_ahb_clk_src",
				      "cpas_ahb_clk",
				      "cpas_core_ahb_clk",
				      "camnoc_axi_clk_src",
				      "camnoc_axi_clk";
			clocks = <&gcc GCC_CAMERA_HF_AXI_CLK>,
				 <&gcc GCC_CAMERA_SF_AXI_CLK>,
				 <&camcc CAM_CC_SLOW_AHB_CLK_SRC>,
				 <&camcc CAM_CC_CPAS_AHB_CLK>,
				 <&camcc CAM_CC_CORE_AHB_CLK>,
				 <&camcc CAM_CC_CAMNOC_AXI_CLK_SRC>,
				 <&camcc CAM_CC_CAMNOC_AXI_CLK>;
			src-clock-name = "camnoc_axi_clk_src";
			clock-rates =
				<0 0 0 0 0 0 0>,
				<0 0 19200000 0 0 19200000 0>,
				<0 0 80000000 0 0 300000000 0>,
				<0 0 80000000 0 0 400000000 0>,
				<0 0 80000000 0 0 400000000 0>,
				<0 0 80000000 0 0 400000000 0>,
				<0 0 80000000 0 0 400000000 0>,
				<0 0 80000000 0 0 480000000 0>;
			clock-cntl-level = "suspend", "minsvs", "lowsvs", "svs",
					   "svs_l1", "nominal", "nominal_l1", "turbo";
			control-camnoc-axi-clk;
			camnoc-bus-width = <32>;
			camnoc-axi-clk-bw-margin-perc = <20>;
			interconnect-names = "cam_ahb",
					     "cam_hf_0_mnoc",
					     "cam_sf_0_mnoc",
					     "cam_sf_icp_mnoc";
			interconnects = <&gem_noc MASTER_AMPSS_M0 QCOM_ICC_TAG_ALWAYS
					 &config_noc SLAVE_CAMERA_CFG QCOM_ICC_TAG_ALWAYS>,
					<&mmss_noc MASTER_CAMNOC_HF QCOM_ICC_TAG_ALWAYS
					 &mc_virt SLAVE_EBI_CH0 QCOM_ICC_TAG_ALWAYS>,
					<&mmss_noc MASTER_CAMNOC_SF QCOM_ICC_TAG_ALWAYS
					 &mc_virt SLAVE_EBI_CH0 QCOM_ICC_TAG_ALWAYS>,
					<&mmss_noc MASTER_CAMNOC_ICP QCOM_ICC_TAG_ALWAYS
					 &mc_virt SLAVE_EBI_CH0 QCOM_ICC_TAG_ALWAYS>;
			cam-ahb-num-cases = <8>;
			cam-ahb-bw-KBps = <0 0>, <0 76800>, <0 76800>, <0 150000>,
					  <0 150000>, <0 300000>, <0 300000>, <0 300000>;
			vdd-corners = <RPMH_REGULATOR_LEVEL_RETENTION
				       RPMH_REGULATOR_LEVEL_MIN_SVS
				       RPMH_REGULATOR_LEVEL_LOW_SVS
				       RPMH_REGULATOR_LEVEL_SVS
				       RPMH_REGULATOR_LEVEL_SVS_L1
				       RPMH_REGULATOR_LEVEL_NOM
				       RPMH_REGULATOR_LEVEL_NOM_L1
				       RPMH_REGULATOR_LEVEL_NOM_L2
				       RPMH_REGULATOR_LEVEL_TURBO
				       RPMH_REGULATOR_LEVEL_TURBO_L1>;
			vdd-corner-ahb-mapping = "suspend", "minsvs",
						 "lowsvs", "svs", "svs_l1",
						 "nominal", "nominal", "nominal",
						 "turbo", "turbo";
			client-id-based;
			client-names = "csiphy0", "csiphy1", "csiphy2", "csiphy3",
				       "csiphy4", "csiphy5", "cci0", "cci1",
				       "csid0", "csid1", "csid2", "csid3",
				       "csid4", "csid5", "csid6", "ife0", "ife1",
				       "ife2", "ife3", "ife4", "ife5", "ife6",
				       "custom0", "ipe0", "cam-cdm-intf0", "cpas-cdm0",
				       "bps0", "icp0", "jpeg-dma0", "jpeg-enc0", "fd0";

			camera-bus-nodes {
				level3-nodes {
					level-index = <3>;
					level3_rt0_rd_wr_sum: level3-rt0-rd-wr-sum {
						cell-index = <0>;
						node-name = "level3-rt0-rd-wr-sum";
						traffic-merge-type = <CAM_CPAS_TRAFFIC_MERGE_SUM>;
						qcom,axi-port-name = "cam_hf_0";
						ib-bw-voting-needed;
						qcom,axi-port-mnoc {
							interconnect-names = "cam_hf_0_mnoc";
							interconnects = <&mmss_noc MASTER_CAMNOC_HF QCOM_ICC_TAG_ALWAYS
									 &mc_virt SLAVE_EBI_CH0 QCOM_ICC_TAG_ALWAYS>;
						};
					};

					level3_nrt0_rd_wr_sum: level3-nrt0-rd-wr-sum {
						cell-index = <1>;
						node-name = "level3-nrt0-rd-wr-sum";
						traffic-merge-type = <CAM_CPAS_TRAFFIC_MERGE_SUM>;
						qcom,axi-port-name = "cam_sf_0";
						qcom,axi-port-mnoc {
							interconnect-names = "cam_sf_0_mnoc";
							interconnects = <&mmss_noc MASTER_CAMNOC_SF QCOM_ICC_TAG_ALWAYS
									 &mc_virt SLAVE_EBI_CH0 QCOM_ICC_TAG_ALWAYS>;
						};
					};

					level3_nrt1_rd_wr_sum: level3-nrt1-rd-wr-sum {
						cell-index = <2>;
						node-name = "level3-nrt1-rd-wr-sum";
						traffic-merge-type = <CAM_CPAS_TRAFFIC_MERGE_SUM>;
						qcom,axi-port-name = "cam_sf_icp";
						qcom,axi-port-mnoc {
							interconnect-names = "cam_sf_icp_mnoc";
							interconnects = <&mmss_noc MASTER_CAMNOC_ICP QCOM_ICC_TAG_ALWAYS
									 &mc_virt SLAVE_EBI_CH0 QCOM_ICC_TAG_ALWAYS>;
						};
					};
				};

				level2-nodes {
					level-index = <2>;
					camnoc-max-needed;
					level2_rt0_wr: level2-rt0-wr {
						cell-index = <3>;
						node-name = "level2-rt0-wr";
						parent-node = <&level3_rt0_rd_wr_sum>;
						traffic-merge-type = <CAM_CPAS_TRAFFIC_MERGE_SUM_INTERLEAVE>;
					};

					level2_rt0_rd: level2-rt0-rd {
						cell-index = <4>;
						node-name = "level2-rt0-rd";
						parent-node = <&level3_rt0_rd_wr_sum>;
						traffic-merge-type = <CAM_CPAS_TRAFFIC_MERGE_SUM_INTERLEAVE>;
					};

					level2_nrt0_wr: level2-nrt0-wr {
						cell-index = <5>;
						node-name = "level2-nrt0-wr";
						parent-node = <&level3_nrt0_rd_wr_sum>;
						traffic-merge-type = <CAM_CPAS_TRAFFIC_MERGE_SUM_INTERLEAVE>;
					};

					level2_nrt0_rd: level2-nrt0-rd {
						cell-index = <6>;
						node-name = "level2-nrt0-rd";
						parent-node = <&level3_nrt0_rd_wr_sum>;
						traffic-merge-type = <CAM_CPAS_TRAFFIC_MERGE_SUM_INTERLEAVE>;
					};

					level2_nrt1_rd: level2-nrt1-rd {
						cell-index = <7>;
						node-name = "level2-nrt1-rd";
						parent-node = <&level3_nrt1_rd_wr_sum>;
						traffic-merge-type = <CAM_CPAS_TRAFFIC_MERGE_SUM>;
						bus-width-factor = <4>;
					};
				};

				level1-nodes {
					level-index = <1>;
					camnoc-max-needed;
					level1_rt0_wr0: level1-rt0-wr0 {
						cell-index = <8>;
						node-name = "level1-rt0-wr0";
						parent-node = <&level2_rt0_wr>;
						traffic-merge-type = <CAM_CPAS_TRAFFIC_MERGE_SUM>;
					};

					level1_rt0_wr1: level1-rt0-wr1 {
						cell-index = <9>;
						node-name = "level1-rt0-wr1";
						parent-node = <&level2_rt0_wr>;
						traffic-merge-type = <CAM_CPAS_TRAFFIC_MERGE_SUM>;
					};

					level1_rt0_rd0: level1-rt0-rd0 {
						cell-index = <10>;
						node-name = "level1-rt0-rd0";
						parent-node = <&level2_rt0_rd>;
						traffic-merge-type = <CAM_CPAS_TRAFFIC_MERGE_SUM>;
					};

					level1_rt0_wr2: level1-rt0-wr2 {
						cell-index = <11>;
						node-name = "level1-rt0-wr2";
						parent-node = <&level2_rt0_wr>;
						traffic-merge-type = <CAM_CPAS_TRAFFIC_MERGE_SUM>;
					};

					level1_nrt0_wr0: level1-nrt0-wr0 {
						cell-index = <12>;
						node-name = "level1-nrt0-wr0";
						parent-node = <&level2_nrt0_wr>;
						traffic-merge-type = <CAM_CPAS_TRAFFIC_MERGE_SUM>;
					};

					level1_nrt0_rd0: level1-nrt0-rd0 {
						cell-index = <13>;
						node-name = "level1-nrt0-rd0";
						parent-node = <&level2_nrt0_rd>;
						traffic-merge-type = <CAM_CPAS_TRAFFIC_MERGE_SUM>;
					};

					level1_nrt0_wr1: level1-nrt0-wr1 {
						cell-index = <14>;
						node-name = "level1-nrt0-wr1";
						parent-node = <&level2_nrt0_wr>;
						traffic-merge-type = <CAM_CPAS_TRAFFIC_MERGE_SUM>;
					};

					level1_nrt0_rd2: level1-nrt0-rd2 {
						cell-index = <15>;
						node-name = "level1-nrt0-rd2";
						parent-node = <&level2_nrt0_rd>;
						traffic-merge-type = <CAM_CPAS_TRAFFIC_MERGE_SUM>;
					};
				};

				level0-nodes {
					level-index = <0>;
					ife0_ubwc_stats_wr: ife0-ubwc-stats-wr {
						cell-index = <16>;
						node-name = "ife0-ubwc-stats-wr";
						client-name = "ife0";
						traffic-data = <CAM_CPAS_PATH_DATA_IFE_UBWC_STATS>;
						traffic-transaction-type = <CAM_CPAS_TRANSACTION_WRITE>;
						constituent-paths = <CAM_CPAS_PATH_DATA_IFE_VID
								     CAM_CPAS_PATH_DATA_IFE_DISP
								     CAM_CPAS_PATH_DATA_IFE_STATS>;
						parent-node = <&level1_rt0_wr0>;
					};

					ife1_ubwc_stats_wr: ife1-ubwc-stats-wr {
						cell-index = <17>;
						node-name = "ife1-ubwc-stats-wr";
						client-name = "ife1";
						traffic-data = <CAM_CPAS_PATH_DATA_IFE_UBWC_STATS>;
						traffic-transaction-type = <CAM_CPAS_TRANSACTION_WRITE>;
						constituent-paths = <CAM_CPAS_PATH_DATA_IFE_VID
								     CAM_CPAS_PATH_DATA_IFE_DISP
								     CAM_CPAS_PATH_DATA_IFE_STATS>;
						parent-node = <&level1_rt0_wr0>;
					};

					ife0_linear_pdaf_wr: ife0-linear-pdaf-wr {
						cell-index = <18>;
						node-name = "ife0-linear-pdaf-wr";
						client-name = "ife0";
						traffic-data = <CAM_CPAS_PATH_DATA_IFE_LINEAR_PDAF>;
						traffic-transaction-type = <CAM_CPAS_TRANSACTION_WRITE>;
						constituent-paths = <CAM_CPAS_PATH_DATA_IFE_LINEAR
								     CAM_CPAS_PATH_DATA_IFE_PDAF>;
						parent-node = <&level1_rt0_wr1>;
					};

					ife1_linear_pdaf_wr: ife1-linear-pdaf-wr {
						cell-index = <19>;
						node-name = "ife1-linear-pdaf-wr";
						client-name = "ife1";
						traffic-data = <CAM_CPAS_PATH_DATA_IFE_LINEAR_PDAF>;
						traffic-transaction-type = <CAM_CPAS_TRANSACTION_WRITE>;
						constituent-paths = <CAM_CPAS_PATH_DATA_IFE_LINEAR
								     CAM_CPAS_PATH_DATA_IFE_PDAF>;
						parent-node = <&level1_rt0_wr1>;
					};

					ife2_rdi_all_wr: ife2-rdi-all-wr {
						cell-index = <20>;
						node-name = "ife2-rdi-all-wr";
						client-name = "ife2";
						traffic-data = <CAM_CPAS_PATH_DATA_IFE_RDI_ALL>;
						traffic-transaction-type = <CAM_CPAS_TRANSACTION_WRITE>;
						constituent-paths = <CAM_CPAS_PATH_DATA_IFE_RDI0
								     CAM_CPAS_PATH_DATA_IFE_RDI1
								     CAM_CPAS_PATH_DATA_IFE_RDI2
								     CAM_CPAS_PATH_DATA_IFE_RDI3>;
						parent-node = <&level1_rt0_wr1>;
					};

					ife3_rdi_all_wr: ife3-rdi-all-wr {
						cell-index = <21>;
						node-name = "ife3-rdi-all-wr";
						client-name = "ife3";
						traffic-data = <CAM_CPAS_PATH_DATA_IFE_RDI_ALL>;
						traffic-transaction-type = <CAM_CPAS_TRANSACTION_WRITE>;
						constituent-paths = <CAM_CPAS_PATH_DATA_IFE_RDI0
								     CAM_CPAS_PATH_DATA_IFE_RDI1
								     CAM_CPAS_PATH_DATA_IFE_RDI2
								     CAM_CPAS_PATH_DATA_IFE_RDI3>;
						parent-node = <&level1_rt0_wr1>;
					};

					ife4_rdi_all_wr: ife4-rdi-all-wr {
						cell-index = <22>;
						node-name = "ife4-rdi-all-wr";
						client-name = "ife4";
						traffic-data = <CAM_CPAS_PATH_DATA_IFE_RDI_ALL>;
						traffic-transaction-type = <CAM_CPAS_TRANSACTION_WRITE>;
						constituent-paths = <CAM_CPAS_PATH_DATA_IFE_RDI0
								     CAM_CPAS_PATH_DATA_IFE_RDI1
								     CAM_CPAS_PATH_DATA_IFE_RDI2
								     CAM_CPAS_PATH_DATA_IFE_RDI3>;
						parent-node = <&level1_rt0_wr1>;
					};

					ife5_rdi_all_wr: ife5-rdi-all-wr {
						cell-index = <23>;
						node-name = "ife5-rdi-all-wr";
						client-name = "ife5";
						traffic-data = <CAM_CPAS_PATH_DATA_IFE_RDI_ALL>;
						traffic-transaction-type = <CAM_CPAS_TRANSACTION_WRITE>;
						constituent-paths = <CAM_CPAS_PATH_DATA_IFE_RDI0
								     CAM_CPAS_PATH_DATA_IFE_RDI1
								     CAM_CPAS_PATH_DATA_IFE_RDI2
								     CAM_CPAS_PATH_DATA_IFE_RDI3>;
						parent-node = <&level1_rt0_wr1>;
					};

					ife0_rdi_all_rd: ife0-rdi-all-rd {
						cell-index = <24>;
						node-name = "ife0-rdi-all-rd";
						client-name = "ife0";
						traffic-data = <CAM_CPAS_PATH_DATA_IFE_RDI_ALL>;
						traffic-transaction-type = <CAM_CPAS_TRANSACTION_READ>;
						constituent-paths = <CAM_CPAS_PATH_DATA_IFE_RDI0
								     CAM_CPAS_PATH_DATA_IFE_RDI1
								     CAM_CPAS_PATH_DATA_IFE_RDI2
								     CAM_CPAS_PATH_DATA_IFE_RDI3>;
						parent-node = <&level1_rt0_rd0>;
					};

					ife1_rdi_all_rd: ife1-rdi-all-rd {
						cell-index = <25>;
						node-name = "ife1-rdi-all-rd";
						client-name = "ife1";
						traffic-data = <CAM_CPAS_PATH_DATA_IFE_RDI_ALL>;
						traffic-transaction-type = <CAM_CPAS_TRANSACTION_READ>;
						constituent-paths = <CAM_CPAS_PATH_DATA_IFE_RDI0
								     CAM_CPAS_PATH_DATA_IFE_RDI1
								     CAM_CPAS_PATH_DATA_IFE_RDI2
								     CAM_CPAS_PATH_DATA_IFE_RDI3>;
						parent-node = <&level1_rt0_rd0>;
					};

					custom0_all_rd: custom0-all-rd {
						cell-index = <26>;
						node-name = "custom0-all-rd";
						client-name = "custom0";
						traffic-data = <CAM_CPAS_PATH_DATA_ALL>;
						traffic-transaction-type = <CAM_CPAS_TRANSACTION_READ>;
						parent-node = <&level1_rt0_rd0>;
					};

					ife0_rdi_pixel_raw_wr: ife0-rdi-pixel-raw-wr {
						cell-index = <27>;
						node-name = "ife0-rdi-pixel-raw-wr";
						client-name = "ife0";
						traffic-data = <CAM_CPAS_PATH_DATA_IFE_RDI_PIXEL_RAW>;
						traffic-transaction-type = <CAM_CPAS_TRANSACTION_WRITE>;
						constituent-paths = <CAM_CPAS_PATH_DATA_IFE_RDI0
								     CAM_CPAS_PATH_DATA_IFE_RDI1
								     CAM_CPAS_PATH_DATA_IFE_RDI2
								     CAM_CPAS_PATH_DATA_IFE_PIXEL_RAW>;
						parent-node = <&level1_rt0_wr2>;
					};

					ife1_rdi_pixel_raw_wr: ife1-rdi-pixel-raw-wr {
						cell-index = <28>;
						node-name = "ife1-rdi-pixel-raw-wr";
						client-name = "ife1";
						traffic-data = <CAM_CPAS_PATH_DATA_IFE_RDI_PIXEL_RAW>;
						traffic-transaction-type = <CAM_CPAS_TRANSACTION_WRITE>;
						constituent-paths = <CAM_CPAS_PATH_DATA_IFE_RDI0
								     CAM_CPAS_PATH_DATA_IFE_RDI1
								     CAM_CPAS_PATH_DATA_IFE_RDI2
								     CAM_CPAS_PATH_DATA_IFE_PIXEL_RAW>;
						parent-node = <&level1_rt0_wr2>;
					};

					ife6_rdi_all_wr: ife6-rdi-all-wr {
						cell-index = <29>;
						node-name = "ife6-rdi-all-wr";
						client-name = "ife6";
						traffic-data = <CAM_CPAS_PATH_DATA_IFE_RDI_ALL>;
						traffic-transaction-type = <CAM_CPAS_TRANSACTION_WRITE>;
						constituent-paths = <CAM_CPAS_PATH_DATA_IFE_RDI0
								     CAM_CPAS_PATH_DATA_IFE_RDI1
								     CAM_CPAS_PATH_DATA_IFE_RDI2
								     CAM_CPAS_PATH_DATA_IFE_RDI3>;
						parent-node = <&level1_rt0_wr2>;
					};

					custom0_all_wr: custom0-all-wr {
						cell-index = <30>;
						node-name = "custom0-all-wr";
						client-name = "custom0";
						traffic-data = <CAM_CPAS_PATH_DATA_ALL>;
						traffic-transaction-type = <CAM_CPAS_TRANSACTION_WRITE>;
						parent-node = <&level1_rt0_wr2>;
					};

					ipe0_all_wr: ipe0-all-wr {
						cell-index = <31>;
						node-name = "ipe0-all-wr";
						client-name = "ipe0";
						traffic-data = <CAM_CPAS_PATH_DATA_ALL>;
						traffic-transaction-type = <CAM_CPAS_TRANSACTION_WRITE>;
						constituent-paths = <CAM_CPAS_PATH_DATA_IPE_WR_VID
								     CAM_CPAS_PATH_DATA_IPE_WR_DISP
								     CAM_CPAS_PATH_DATA_IPE_WR_REF>;
						parent-node = <&level1_nrt0_wr0>;
					};

					bps0_all_wr: bps0-all-wr {
						cell-index = <32>;
						node-name = "bps0-all-wr";
						client-name = "bps0";
						traffic-data = <CAM_CPAS_PATH_DATA_ALL>;
						traffic-transaction-type = <CAM_CPAS_TRANSACTION_WRITE>;
						parent-node = <&level1_nrt0_wr0>;
					};

					ipe0_ref_rd: ipe0-ref-rd {
						cell-index = <33>;
						node-name = "ipe0-ref-rd";
						client-name = "ipe0";
						traffic-data = <CAM_CPAS_PATH_DATA_IPE_RD_REF>;
						traffic-transaction-type = <CAM_CPAS_TRANSACTION_READ>;
						parent-node = <&level1_nrt0_rd0>;
					};

					bps0_all_rd: bps0-all-rd {
						cell-index = <34>;
						node-name = "bps0-all-rd";
						client-name = "bps0";
						traffic-data = <CAM_CPAS_PATH_DATA_ALL>;
						traffic-transaction-type = <CAM_CPAS_TRANSACTION_READ>;
						parent-node = <&level1_nrt0_rd0>;
					};

					ipe0_in_rd: ipe0-in-rd {
						cell-index = <35>;
						node-name = "ipe0-in-rd";
						client-name = "ipe0";
						traffic-data = <CAM_CPAS_PATH_DATA_IPE_RD_IN>;
						traffic-transaction-type = <CAM_CPAS_TRANSACTION_READ>;
						parent-node = <&level2_nrt0_rd>;
					};

					jpeg_enc0_all_wr: jpeg-enc0-all-wr {
						cell-index = <36>;
						node-name = "jpeg-enc0-all-wr";
						client-name = "jpeg-enc0";
						traffic-data = <CAM_CPAS_PATH_DATA_ALL>;
						traffic-transaction-type = <CAM_CPAS_TRANSACTION_WRITE>;
						parent-node = <&level1_nrt0_wr1>;
					};

					jpeg_dma0_all_wr: jpeg-dma0-all-wr {
						cell-index = <37>;
						node-name = "jpeg-dma0-all-wr";
						client-name = "jpeg-dma0";
						traffic-data = <CAM_CPAS_PATH_DATA_ALL>;
						traffic-transaction-type = <CAM_CPAS_TRANSACTION_WRITE>;
						parent-node = <&level1_nrt0_wr1>;
					};

					jpeg_enc0_all_rd: jpeg-enc0-all-rd {
						cell-index = <38>;
						node-name = "jpeg-enc0-all-rd";
						client-name = "jpeg-enc0";
						traffic-data = <CAM_CPAS_PATH_DATA_ALL>;
						traffic-transaction-type = <CAM_CPAS_TRANSACTION_READ>;
						parent-node = <&level1_nrt0_rd2>;
					};

					jpeg_dma0_all_rd: jpeg-dma0-all-rd {
						cell-index = <39>;
						node-name = "jpeg-dma0-all-rd";
						client-name = "jpeg-dma0";
						traffic-data = <CAM_CPAS_PATH_DATA_ALL>;
						traffic-transaction-type = <CAM_CPAS_TRANSACTION_READ>;
						parent-node = <&level1_nrt0_rd2>;
					};

					fd0_all_wr: fd0-all-wr {
						cell-index = <40>;
						node-name = "fd0-all-wr";
						client-name = "fd0";
						traffic-data = <CAM_CPAS_PATH_DATA_ALL>;
						traffic-transaction-type = <CAM_CPAS_TRANSACTION_WRITE>;
						parent-node = <&level2_nrt0_wr>;
					};

					fd0_all_rd: fd0-all-rd {
						cell-index = <41>;
						node-name = "fd0-all-rd";
						client-name = "fd0";
						traffic-data = <CAM_CPAS_PATH_DATA_ALL>;
						traffic-transaction-type = <CAM_CPAS_TRANSACTION_READ>;
						parent-node = <&level2_nrt0_rd>;
					};

					cpas_cdm0_all_rd: cpas-cdm0-all-rd {
						cell-index = <42>;
						node-name = "cpas-cdm0-all-rd";
						client-name = "cpas-cdm0";
						traffic-data = <CAM_CPAS_PATH_DATA_ALL>;
						traffic-transaction-type = <CAM_CPAS_TRANSACTION_READ>;
						parent-node = <&level2_nrt0_rd>;
					};

					icp0_all_rd: icp0-all-rd {
						cell-index = <43>;
						node-name = "icp0-all-rd";
						client-name = "icp0";
						traffic-data = <CAM_CPAS_PATH_DATA_ALL>;
						traffic-transaction-type = <CAM_CPAS_TRANSACTION_READ>;
						parent-node = <&level2_nrt1_rd>;
					};
				};
			};
		};

		qcom,cam-cdm-intf {
			compatible = "qcom,cam-cdm-intf";
			cell-index = <0>;
			label = "cam-cdm-intf";
			num-hw-cdm = <3>;
			cdm-client-names = "vfe",
					   "jpegdma",
					   "jpegenc",
					   "fd";
			status = "okay";
		};

		qcom,cpas-cdm0@ac4d000 {
			cell-index = <0>;
			compatible = "qcom,cam170-cpas-cdm0";
			label = "cpas-cdm";
			reg = <0x0ac4d000 0x1000>;
			reg-names = "cpas-cdm";
			reg-cam-base = <0x4d000>;
			interrupts = <GIC_SPI 461 IRQ_TYPE_EDGE_RISING>;
			interrupt-names = "cpas-cdm";
			regulator-names = "camss";
			camss-supply = <&cam_cc_titan_top_gdsc>;
			clock-names = "cam_cc_cpas_slow_ahb_clk",
				      "cam_cc_cpas_ahb_clk";
			clocks = <&camcc CAM_CC_SLOW_AHB_CLK_SRC>,
				 <&camcc CAM_CC_CPAS_AHB_CLK>;
			clock-rates = <0 0>;
			clock-cntl-level = "svs";
			cdm-client-names = "ife";
			status = "okay";
		};

		qcom,cpas-cdm1@acb4200 {
			cell-index = <1>;
			compatible = "qcom,cam480-cpas-cdm1";
			label = "cpas-cdm";
			reg = <0x0acb4200 0x1000>;
			reg-names = "cpas-cdm";
			reg-cam-base = <0xb4200>;
			interrupts = <GIC_SPI 456 IRQ_TYPE_EDGE_RISING>;
			interrupt-names = "cpas-cdm";
			regulator-names = "camss";
			camss-supply = <&cam_cc_titan_top_gdsc>;
			clock-names = "cam_cc_cpas_slow_ahb_clk",
				      "cam_cc_cpas_ahb_clk";
			clocks = <&camcc CAM_CC_SLOW_AHB_CLK_SRC>,
				 <&camcc CAM_CC_CPAS_AHB_CLK>;
			clock-rates = <0 0>;
			clock-cntl-level = "svs";
			cdm-client-names = "ife0";
			status = "disabled";
		};

		qcom,cpas-cdm2@acc3200 {
			cell-index = <2>;
			compatible = "qcom,cam480-cpas-cdm2";
			label = "cpas-cdm";
			reg = <0x0acc3200 0x1000>;
			reg-names = "cpas-cdm";
			reg-cam-base = <0xc3200>;
			interrupts = <GIC_SPI 287 IRQ_TYPE_EDGE_RISING>;
			interrupt-names = "cpas-cdm";
			regulator-names = "camss";
			camss-supply = <&cam_cc_titan_top_gdsc>;
			clock-names = "cam_cc_cpas_slow_ahb_clk",
				      "cam_cc_cpas_ahb_clk";
			clocks = <&camcc CAM_CC_SLOW_AHB_CLK_SRC>,
				 <&camcc CAM_CC_CPAS_AHB_CLK>;
			clock-rates = <0 0>;
			clock-cntl-level = "svs";
			cdm-client-names = "ife1";
			status = "disabled";
		};

		qcom,cam-isp {
			compatible = "qcom,cam-isp";
			arch-compat = "ife";
			status = "okay";
		};

		cam_csid0: qcom,csid0@acb5200 {
			cell-index = <0>;
			compatible = "qcom,csid480";
			reg-names = "csid";
			reg = <0x0acb5200 0x1000>;
			reg-cam-base = <0xb5200>;
			interrupt-names = "csid";
			interrupts = <GIC_SPI 464 IRQ_TYPE_EDGE_RISING>;
			regulator-names = "camss", "ife0";
			camss-supply = <&cam_cc_titan_top_gdsc>;
			ife0-supply = <&cam_cc_ife_0_gdsc>;
			clock-names = "ife_csid_clk_src",
				      "ife_csid_clk",
				      "cphy_rx_clk_src",
				      "ife_cphy_rx_clk",
				      "ife_clk_src",
				      "ife_clk",
				      "ife_0_areg",
				      "ife_0_ahb",
				      "ife_axi_clk";
			clocks = <&camcc CAM_CC_IFE_0_CSID_CLK_SRC>,
				 <&camcc CAM_CC_IFE_0_CSID_CLK>,
				 <&camcc CAM_CC_CPHY_RX_CLK_SRC>,
				 <&camcc CAM_CC_IFE_0_CPHY_RX_CLK>,
				 <&camcc CAM_CC_IFE_0_CLK_SRC>,
				 <&camcc CAM_CC_IFE_0_CLK>,
				 <&camcc CAM_CC_IFE_0_AREG_CLK>,
				 <&camcc CAM_CC_IFE_0_AHB_CLK>,
				 <&camcc CAM_CC_IFE_0_AXI_CLK>;
			clock-rates =
				<400000000 0 400000000 0 350000000 0 100000000 0 0>,
				<400000000 0 400000000 0 475000000 0 200000000 0 0>,
				<400000000 0 400000000 0 576000000 0 300000000 0 0>,
				<400000000 0 400000000 0 720000000 0 400000000 0 0>;
			clock-cntl-level = "lowsvs", "svs", "svs_l1", "turbo";
			src-clock-name = "ife_csid_clk_src";
			clock-control-debugfs = "true";
			status = "okay";
		};

		cam_vfe0: qcom,ife0@acb4000 {
			cell-index = <0>;
			compatible = "qcom,vfe480";
			reg-names = "ife", "cam_camnoc";
			reg = <0x0acb4000 0xd000>,
			      <0x0ac42000 0x8000>;
			reg-cam-base = <0xb4000 0x42000>;
			interrupt-names = "ife";
			interrupts = <GIC_SPI 465 IRQ_TYPE_EDGE_RISING>;
			regulator-names = "camss", "ife0";
			camss-supply = <&cam_cc_titan_top_gdsc>;
			ife0-supply = <&cam_cc_ife_0_gdsc>;
			clock-names = "ife_0_ahb",
				      "ife_0_areg",
				      "ife_clk_src",
				      "ife_clk",
				      "ife_axi_clk";
			clocks = <&camcc CAM_CC_IFE_0_AHB_CLK>,
				 <&camcc CAM_CC_IFE_0_AREG_CLK>,
				 <&camcc CAM_CC_IFE_0_CLK_SRC>,
				 <&camcc CAM_CC_IFE_0_CLK>,
				 <&camcc CAM_CC_IFE_0_AXI_CLK>;
			clock-rates =
				<0 100000000 350000000 0 0>,
				<0 200000000 475000000 0 0>,
				<0 300000000 576000000 0 0>,
				<0 400000000 720000000 0 0>;
			clock-cntl-level = "lowsvs", "svs", "svs_l1", "turbo";
			src-clock-name = "ife_clk_src";
			scl-clk-names = "ife_0_areg";
			clock-control-debugfs = "true";
			clock-names-option = "ife_dsp_clk";
			clocks-option = <&camcc CAM_CC_IFE_0_DSP_CLK>;
			clock-rates-option = <720000000>;
			ubwc-static-cfg = <0x1026 0x1036>;
			status = "okay";
		};

		cam_csid1: qcom,csid1@acc4200 {
			cell-index = <1>;
			compatible = "qcom,csid480";
			reg-names = "csid";
			reg = <0x0acc4200 0x1000>;
			reg-cam-base = <0xc4200>;
			interrupt-names = "csid";
			interrupts = <GIC_SPI 466 IRQ_TYPE_EDGE_RISING>;
			regulator-names = "camss", "ife1";
			camss-supply = <&cam_cc_titan_top_gdsc>;
			ife1-supply = <&cam_cc_ife_1_gdsc>;
			clock-names = "ife_csid_clk_src",
				      "ife_csid_clk",
				      "cphy_rx_clk_src",
				      "ife_cphy_rx_clk",
				      "ife_clk_src",
				      "ife_clk",
				      "ife_1_areg",
				      "ife_1_ahb",
				      "ife_axi_clk";
			clocks = <&camcc CAM_CC_IFE_1_CSID_CLK_SRC>,
				 <&camcc CAM_CC_IFE_1_CSID_CLK>,
				 <&camcc CAM_CC_CPHY_RX_CLK_SRC>,
				 <&camcc CAM_CC_IFE_1_CPHY_RX_CLK>,
				 <&camcc CAM_CC_IFE_1_CLK_SRC>,
				 <&camcc CAM_CC_IFE_1_CLK>,
				 <&camcc CAM_CC_IFE_1_AREG_CLK>,
				 <&camcc CAM_CC_IFE_1_AHB_CLK>,
				 <&camcc CAM_CC_IFE_1_AXI_CLK>;
			clock-rates =
				<400000000 0 400000000 0 350000000 0 100000000 0 0>,
				<400000000 0 400000000 0 475000000 0 200000000 0 0>,
				<400000000 0 400000000 0 576000000 0 300000000 0 0>,
				<400000000 0 400000000 0 720000000 0 400000000 0 0>;
			clock-cntl-level = "lowsvs", "svs", "svs_l1", "turbo";
			src-clock-name = "ife_csid_clk_src";
			clock-control-debugfs = "true";
			status = "okay";
		};

		cam_vfe1: qcom,ife1@acc3000 {
			cell-index = <1>;
			compatible = "qcom,vfe480";
			reg-names = "ife", "cam_camnoc";
			reg = <0x0acc3000 0xd000>,
			      <0x0ac42000 0x8000>;
			reg-cam-base = <0xc3000 0x42000>;
			interrupt-names = "ife";
			interrupts = <GIC_SPI 467 IRQ_TYPE_EDGE_RISING>;
			regulator-names = "camss", "ife1";
			camss-supply = <&cam_cc_titan_top_gdsc>;
			ife1-supply = <&cam_cc_ife_1_gdsc>;
			clock-names = "ife_1_ahb",
				      "ife_1_areg",
				      "ife_clk_src",
				      "ife_clk",
				      "ife_axi_clk";
			clocks = <&camcc CAM_CC_IFE_1_AHB_CLK>,
				 <&camcc CAM_CC_IFE_1_AREG_CLK>,
				 <&camcc CAM_CC_IFE_1_CLK_SRC>,
				 <&camcc CAM_CC_IFE_1_CLK>,
				 <&camcc CAM_CC_IFE_1_AXI_CLK>;
			clock-rates =
				<0 100000000 350000000 0 0>,
				<0 200000000 475000000 0 0>,
				<0 300000000 576000000 0 0>,
				<0 400000000 720000000 0 0>;
			clock-cntl-level = "lowsvs", "svs", "svs_l1", "turbo";
			src-clock-name = "ife_clk_src";
			scl-clk-names = "ife_1_areg";
			clock-control-debugfs = "true";
			clock-names-option = "ife_dsp_clk";
			clocks-option = <&camcc CAM_CC_IFE_1_DSP_CLK>;
			clock-rates-option = <720000000>;
			ubwc-static-cfg = <0x1026 0x1036>;
			status = "okay";
		};

		cam_csid_lite0: qcom,csid-lite0@acd9200 {
			cell-index = <2>;
			compatible = "qcom,csid-lite480";
			reg-names = "csid-lite";
			reg = <0x0acd9200 0x1000>;
			reg-cam-base = <0xd9200>;
			interrupt-names = "csid-lite";
			interrupts = <GIC_SPI 468 IRQ_TYPE_EDGE_RISING>;
			regulator-names = "camss";
			camss-supply = <&cam_cc_titan_top_gdsc>;
			clock-names = "ife_csid_clk_src",
				      "ife_csid_clk",
				      "cphy_rx_clk_src",
				      "ife_cphy_rx_clk",
				      "ife_clk_src",
				      "ife_lite_ahb",
				      "ife_clk";
			clocks = <&camcc CAM_CC_IFE_LITE_CSID_CLK_SRC>,
				 <&camcc CAM_CC_IFE_LITE_CSID_CLK>,
				 <&camcc CAM_CC_CPHY_RX_CLK_SRC>,
				 <&camcc CAM_CC_IFE_LITE_CPHY_RX_CLK>,
				 <&camcc CAM_CC_IFE_LITE_CLK_SRC>,
				 <&camcc CAM_CC_IFE_LITE_AHB_CLK>,
				 <&camcc CAM_CC_IFE_LITE_CLK>;
			clock-rates =
				<400000000 0 0 0 400000000 0 0>,
				<400000000 0 0 0 480000000 0 0>,
				<400000000 0 0 0 480000000 0 0>,
				<400000000 0 0 0 480000000 0 0>;
			clock-cntl-level = "lowsvs", "svs", "svs_l1", "turbo";
			src-clock-name = "ife_csid_clk_src";
			clock-control-debugfs = "true";
			status = "okay";
		};

		cam_vfe_lite0: qcom,ife-lite0@acd9000 {
			cell-index = <2>;
			compatible = "qcom,vfe-lite480";
			reg-names = "ife-lite";
			reg = <0x0acd9000 0x2200>;
			reg-cam-base = <0xd9000>;
			interrupt-names = "ife-lite";
			interrupts = <GIC_SPI 469 IRQ_TYPE_EDGE_RISING>;
			regulator-names = "camss";
			camss-supply = <&cam_cc_titan_top_gdsc>;
			clock-names = "ife_lite_ahb",
				      "ife_lite_axi",
				      "ife_clk_src",
				      "ife_clk";
			clocks = <&camcc CAM_CC_IFE_LITE_AHB_CLK>,
				 <&camcc CAM_CC_IFE_LITE_AXI_CLK>,
				 <&camcc CAM_CC_IFE_LITE_CLK_SRC>,
				 <&camcc CAM_CC_IFE_LITE_CLK>;
			clock-rates =
				<0 0 400000000 0>,
				<0 0 480000000 0>,
				<0 0 480000000 0>,
				<0 0 480000000 0>;
			clock-cntl-level = "lowsvs", "svs", "svs_l1", "turbo";
			src-clock-name = "ife_clk_src";
			clock-control-debugfs = "true";
			status = "okay";
		};

		cam_csid_lite1: qcom,csid-lite1@acdb400 {
			cell-index = <3>;
			compatible = "qcom,csid-lite480";
			reg-names = "csid-lite";
			reg = <0x0acdb400 0x1000>;
			reg-cam-base = <0xdb400>;
			interrupt-names = "csid-lite";
			interrupts = <GIC_SPI 359 IRQ_TYPE_EDGE_RISING>;
			regulator-names = "camss";
			camss-supply = <&cam_cc_titan_top_gdsc>;
			clock-names = "ife_csid_clk_src",
				      "ife_csid_clk",
				      "cphy_rx_clk_src",
				      "ife_cphy_rx_clk",
				      "ife_clk_src",
				      "ife_lite_ahb",
				      "ife_clk";
			clocks = <&camcc CAM_CC_IFE_LITE_CSID_CLK_SRC>,
				 <&camcc CAM_CC_IFE_LITE_CSID_CLK>,
				 <&camcc CAM_CC_CPHY_RX_CLK_SRC>,
				 <&camcc CAM_CC_IFE_LITE_CPHY_RX_CLK>,
				 <&camcc CAM_CC_IFE_LITE_CLK_SRC>,
				 <&camcc CAM_CC_IFE_LITE_AHB_CLK>,
				 <&camcc CAM_CC_IFE_LITE_CLK>;
			clock-rates =
				<400000000 0 0 0 400000000 0 0>,
				<400000000 0 0 0 480000000 0 0>,
				<400000000 0 0 0 480000000 0 0>,
				<400000000 0 0 0 480000000 0 0>;
			clock-cntl-level = "lowsvs", "svs", "svs_l1", "turbo";
			src-clock-name = "ife_csid_clk_src";
			clock-control-debugfs = "true";
			status = "okay";
		};

		cam_vfe_lite1: qcom,ife-lite1@acdb200 {
			cell-index = <3>;
			compatible = "qcom,vfe-lite480";
			reg-names = "ife-lite";
			reg = <0x0acdb200 0x2200>;
			reg-cam-base = <0xdb200>;
			interrupt-names = "ife-lite";
			interrupts = <GIC_SPI 360 IRQ_TYPE_EDGE_RISING>;
			regulator-names = "camss";
			camss-supply = <&cam_cc_titan_top_gdsc>;
			clock-names = "ife_lite_ahb",
				      "ife_lite_axi",
				      "ife_clk_src",
				      "ife_clk";
			clocks = <&camcc CAM_CC_IFE_LITE_AHB_CLK>,
				 <&camcc CAM_CC_IFE_LITE_AXI_CLK>,
				 <&camcc CAM_CC_IFE_LITE_CLK_SRC>,
				 <&camcc CAM_CC_IFE_LITE_CLK>;
			clock-rates =
				<0 0 400000000 0>,
				<0 0 480000000 0>,
				<0 0 480000000 0>,
				<0 0 480000000 0>;
			clock-cntl-level = "lowsvs", "svs", "svs_l1", "turbo";
			src-clock-name = "ife_clk_src";
			clock-control-debugfs = "true";
			status = "okay";
		};

		qcom,cam-icp {
			compatible = "qcom,cam-icp";
			compat-hw-name = "qcom,a5",
					 "qcom,ipe0",
					 "qcom,bps";
			num-a5 = <1>;
			num-ipe = <1>;
			num-bps = <1>;
			status = "okay";
			icp_pc_en;
			ipe_bps_pc_en;
		};

		cam_a5: qcom,a5@ac00000 {
			cell-index = <0>;
			compatible = "qcom,cam-a5";
			reg = <0x0ac00000 0x6000>,
			      <0x0ac10000 0x8000>,
			      <0x0ac18000 0x3000>;
			reg-names = "a5_qgic", "a5_sierra", "a5_csr";
			reg-cam-base = <0x00000 0x10000 0x18000>;
			interrupts = <GIC_SPI 463 IRQ_TYPE_EDGE_RISING>;
			interrupt-names = "a5";
			regulator-names = "camss-vdd";
			camss-vdd-supply = <&cam_cc_titan_top_gdsc>;
			clock-names = "soc_fast_ahb",
				      "icp_ahb_clk",
				      "icp_clk_src",
				      "icp_clk";
			src-clock-name = "icp_clk_src";
			clocks = <&camcc CAM_CC_FAST_AHB_CLK_SRC>,
				 <&camcc CAM_CC_ICP_AHB_CLK>,
				 <&camcc CAM_CC_ICP_CLK_SRC>,
				 <&camcc CAM_CC_ICP_CLK>;
			clock-rates =
				<100000000 0 400000000 0>,
				<200000000 0 480000000 0>,
				<300000000 0 600000000 0>,
				<400000000 0 600000000 0>,
				<400000000 0 600000000 0>;
			clock-cntl-level = "lowsvs", "svs", "svs_l1",
					   "nominal", "turbo";
			fw_name = "CAMERA_ICP.elf";
			ubwc-ipe-fetch-cfg = <0x707b 0x7083>;
			ubwc-ipe-write-cfg = <0x161ef 0x1620f>;
			ubwc-bps-fetch-cfg = <0x707b 0x7083>;
			ubwc-bps-write-cfg = <0x161ef 0x1620f>;
			status = "okay";
		};

		cam_ipe0: qcom,ipe0@ac9a000 {
			cell-index = <0>;
			compatible = "qcom,cam-ipe";
			reg = <0x0ac9a000 0xc000>;
			reg-names = "ipe0_top";
			reg-cam-base = <0x9a000>;
			regulator-names = "ipe0-vdd";
			ipe0-vdd-supply = <&cam_cc_ipe_0_gdsc>;
			clock-names = "ipe_0_ahb_clk",
				      "ipe_0_areg_clk",
				      "ipe_0_axi_clk",
				      "ipe_0_clk_src",
				      "ipe_0_clk";
			src-clock-name = "ipe_0_clk_src";
			clock-control-debugfs = "true";
			clocks = <&camcc CAM_CC_IPE_0_AHB_CLK>,
				 <&camcc CAM_CC_IPE_0_AREG_CLK>,
				 <&camcc CAM_CC_IPE_0_AXI_CLK>,
				 <&camcc CAM_CC_IPE_0_CLK_SRC>,
				 <&camcc CAM_CC_IPE_0_CLK>;
			clock-rates =
				<0 0 0 300000000 0>,
				<0 0 0 475000000 0>,
				<0 0 0 525000000 0>,
				<0 0 0 700000000 0>,
				<0 0 0 700000000 0>;
			clock-cntl-level = "lowsvs", "svs", "svs_l1",
					   "nominal", "turbo";
			status = "okay";
		};

		cam_bps: qcom,bps@ac7a000 {
			cell-index = <0>;
			compatible = "qcom,cam-bps";
			reg = <0x0ac7a000 0x8000>;
			reg-names = "bps_top";
			reg-cam-base = <0x7a000>;
			regulator-names = "bps-vdd";
			bps-vdd-supply = <&cam_cc_bps_gdsc>;
			clock-names = "bps_ahb_clk",
				      "bps_areg_clk",
				      "bps_axi_clk",
				      "bps_clk_src",
				      "bps_clk";
			src-clock-name = "bps_clk_src";
			clock-control-debugfs = "true";
			clocks = <&camcc CAM_CC_BPS_AHB_CLK>,
				 <&camcc CAM_CC_BPS_AREG_CLK>,
				 <&camcc CAM_CC_BPS_AXI_CLK>,
				 <&camcc CAM_CC_BPS_CLK_SRC>,
				 <&camcc CAM_CC_BPS_CLK>;
			clock-rates =
				<0 0 0 200000000 0>,
				<0 0 0 400000000 0>,
				<0 0 0 480000000 0>,
				<0 0 0 600000000 0>,
				<0 0 0 600000000 0>;
			clock-cntl-level = "lowsvs", "svs", "svs_l1",
					   "nominal", "turbo";
			status = "okay";
		};

		qcom,cam-jpeg {
			compatible = "qcom,cam-jpeg";
			compat-hw-name = "qcom,jpegenc",
					 "qcom,jpegdma";
			num-jpeg-enc = <1>;
			num-jpeg-dma = <1>;
			status = "okay";
		};

		cam_jpeg_enc: qcom,jpegenc@ac53000 {
			cell-index = <0>;
			compatible = "qcom,cam_jpeg_enc";
			reg-names = "jpege_hw";
			reg = <0x0ac53000 0x4000>;
			reg-cam-base = <0x53000>;
			interrupt-names = "jpeg";
			interrupts = <GIC_SPI 474 IRQ_TYPE_EDGE_RISING>;
			regulator-names = "camss-vdd";
			camss-vdd-supply = <&cam_cc_titan_top_gdsc>;
			clock-names = "jpegenc_clk_src",
				      "jpegenc_clk";
			clocks = <&camcc CAM_CC_JPEG_CLK_SRC>,
				 <&camcc CAM_CC_JPEG_CLK>;
			clock-rates = <600000000 0>;
			src-clock-name = "jpegenc_clk_src";
			clock-cntl-level = "nominal";
			status = "okay";
		};

		cam_jpeg_dma: qcom,jpegdma@ac57000 {
			cell-index = <0>;
			compatible = "qcom,cam_jpeg_dma";
			reg-names = "jpegdma_hw";
			reg = <0x0ac57000 0x4000>;
			reg-cam-base = <0x57000>;
			interrupt-names = "jpegdma";
			interrupts = <GIC_SPI 475 IRQ_TYPE_EDGE_RISING>;
			regulator-names = "camss-vdd";
			camss-vdd-supply = <&cam_cc_titan_top_gdsc>;
			clock-names = "jpegdma_clk_src",
				      "jpegdma_clk";
			clocks = <&camcc CAM_CC_JPEG_CLK_SRC>,
				 <&camcc CAM_CC_JPEG_CLK>;
			clock-rates = <600000000 0>;
			src-clock-name = "jpegdma_clk_src";
			clock-cntl-level = "nominal";
			status = "okay";
		};
	};
};

&tlmm {
	cam_sensor_front_clock_active: cam-sensor-front-clock-active-state {
		pins = "gpio98";
		function = "cam_mclk";
		bias-disable;
		drive-strength = <2>;
	};

	cam_sensor_front_clock_suspend: cam-sensor-front-clock-suspend-state {
		pins = "gpio98";
		function = "cam_mclk";
		bias-pull-down;
		drive-strength = <2>;
	};

	cam_sensor_front_reset_active: cam-sensor-front-reset-active-state {
		pins = "gpio144";
		function = "gpio";
		bias-disable;
		drive-strength = <2>;
	};

	cam_sensor_front_reset_suspend: cam-sensor-front-reset-suspend-state {
		pins = "gpio144";
		function = "gpio";
		bias-pull-down;
		drive-strength = <2>;
		output-low;
	};

	cam_sensor_front_avdd_active: cam-sensor-front-avdd-active-state {
		pins = "gpio156";
		function = "gpio";
		bias-disable;
		drive-strength = <2>;
	};

	cam_sensor_front_avdd_suspend: cam-sensor-front-avdd-suspend-state {
		pins = "gpio156";
		function = "gpio";
		bias-pull-down;
		drive-strength = <2>;
		output-low;
	};

	cam_sensor_rear_0_clock_active: cam-sensor-rear-0-clock-active-state {
		pins = "gpio94";
		function = "cam_mclk";
		bias-disable;
		drive-strength = <2>;
	};

	cam_sensor_rear_0_clock_suspend: cam-sensor-rear-0-clock-suspend-state {
		pins = "gpio94";
		function = "cam_mclk";
		bias-pull-down;
		drive-strength = <2>;
	};

	cam_sensor_rear_0_reset_active: cam-sensor-rear-0-reset-active-state {
		pins = "gpio78";
		function = "gpio";
		bias-disable;
		drive-strength = <2>;
	};

	cam_sensor_rear_0_reset_suspend: cam-sensor-rear-0-reset-suspend-state {
		pins = "gpio78";
		function = "gpio";
		bias-disable;
		drive-strength = <2>;
	};

	cam_sensor_rear_0_avdd_active: cam-sensor-rear-0-avdd-active-state {
		pins = "gpio139";
		function = "gpio";
		bias-disable;
		drive-strength = <2>;
	};

	cam_sensor_rear_0_avdd_suspend: cam-sensor-rear-0-avdd-suspend-state {
		pins = "gpio139";
		function = "gpio";
		bias-disable;
		drive-strength = <2>;
	};

	cam_sensor_rear_0_dvdd_active: cam-sensor-rear-0-dvdd-active-state {
		pins = "gpio117";
		function = "gpio";
		bias-disable;
		drive-strength = <2>;
	};

	cam_sensor_rear_0_dvdd_suspend: cam-sensor-rear-0-dvdd-suspend-state {
		pins = "gpio117";
		function = "gpio";
		bias-disable;
		drive-strength = <2>;
	};

	cam_sensor_rear_0_ois_active: cam-sensor-rear-0-ois-active-state {
		pins = "gpio140";
		function = "gpio";
		bias-disable;
		drive-strength = <2>;
	};

	cam_sensor_rear_0_ois_suspend: cam-sensor-rear-0-ois-suspend-state {
		pins = "gpio140";
		function = "gpio";
		bias-disable;
		drive-strength = <2>;
	};

	cam_sensor_rear_1_clock_active: cam-sensor-rear-1-clock-active-state {
		pins = "gpio95";
		function = "cam_mclk";
		bias-disable;
		drive-strength = <2>;
	};

	cam_sensor_rear_1_clock_suspend: cam-sensor-rear-1-clock-suspend-state {
		pins = "gpio95";
		function = "cam_mclk";
		bias-pull-down;
		drive-strength = <2>;
	};

	cam_sensor_rear_1_reset_active: cam-sensor-rear-1-reset-active-state {
		pins = "gpio84";
		function = "gpio";
		bias-disable;
		drive-strength = <2>;
	};

	cam_sensor_rear_1_reset_suspend: cam-sensor-rear-1-reset-suspend-state {
		pins = "gpio84";
		function = "gpio";
		bias-disable;
		drive-strength = <2>;
	};

	cam_sensor_rear_1_avdd_active: cam-sensor-rear-1-avdd-active-state {
		pins = "gpio114";
		function = "gpio";
		bias-disable;
		drive-strength = <2>;
	};

	cam_sensor_rear_1_avdd_suspend: cam-sensor-rear-1-avdd-suspend-state {
		pins = "gpio114";
		function = "gpio";
		bias-disable;
		drive-strength = <2>;
	};

	cam_sensor_rear_2_clock_active: cam-sensor-rear-2-clock-active-state {
		pins = "gpio97";
		function = "cam_mclk";
		bias-disable;
		drive-strength = <2>;
	};

	cam_sensor_rear_2_clock_suspend: cam-sensor-rear-2-clock-suspend-state {
		pins = "gpio97";
		function = "cam_mclk";
		bias-pull-down;
		drive-strength = <2>;
	};

	cam_sensor_rear_2_reset_active: cam-sensor-rear-2-reset-active-state {
		pins = "gpio92";
		function = "gpio";
		bias-disable;
		drive-strength = <2>;
	};

	cam_sensor_rear_2_reset_suspend: cam-sensor-rear-2-reset-suspend-state {
		pins = "gpio92";
		function = "gpio";
		bias-disable;
		drive-strength = <2>;
	};

	cam_sensor_rear_3_clock_active: cam-sensor-rear-3-clock-active-state {
		pins = "gpio96";
		function = "cam_mclk";
		bias-disable;
		drive-strength = <2>;
	};

	cam_sensor_rear_3_clock_suspend: cam-sensor-rear-3-clock-suspend-state {
		pins = "gpio96";
		function = "cam_mclk";
		bias-pull-down;
		drive-strength = <2>;
	};

	cam_sensor_rear_3_reset_active: cam-sensor-rear-3-reset-active-state {
		pins = "gpio90";
		function = "gpio";
		bias-disable;
		drive-strength = <2>;
	};

	cam_sensor_rear_3_reset_suspend: cam-sensor-rear-3-reset-suspend-state {
		pins = "gpio90";
		function = "gpio";
		bias-disable;
		drive-strength = <2>;
	};

	cam_sensor_rear_3_custom_active: cam-sensor-rear-3-custom-active-state {
		pins = "gpio74";
		function = "gpio";
		bias-disable;
		drive-strength = <2>;
	};

	cam_sensor_rear_3_custom_suspend: cam-sensor-rear-3-custom-suspend-state {
		pins = "gpio74";
		function = "gpio";
		bias-disable;
		drive-strength = <2>;
	};
};
